AUTOSAR XML (schema 4-2-1)
standard types defined: boolean, float32, sint8, uint16, uint8, boolean_CompuMethod, boolean_DataConstr, float32_DataConstr, sint8_DataConstr, uint16_DataConstr, uint8_DataConstr
package /ComponentTypes
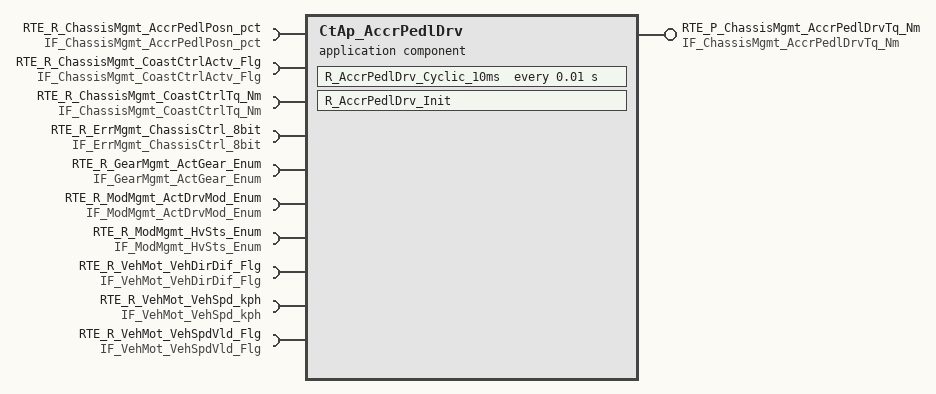
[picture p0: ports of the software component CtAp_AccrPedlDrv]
  application sw component type CtAp_AccrPedlDrv
    provide port RTE_P_ChassisMgmt_AccrPedlDrvTq_Nm: nonqueued-sender-com-spec{data-element=tec_ChassisMgmt_AccrPedlDrvTq_Nm, init-value=0}, provided-interface=IF_ChassisMgmt_AccrPedlDrvTq_Nm
    10 x require port:
      RTE_R_ChassisMgmt_AccrPedlPosn_pct: nonqueued-receiver-com-spec{data-element=tec_ChassisMgmt_AccrPedlPosn_pct, filter=data-filter-type=ALWAYS, init-value=0}, required-interface=IF_ChassisMgmt_AccrPedlPosn_pct
      RTE_R_ChassisMgmt_CoastCtrlActv_Flg: nonqueued-receiver-com-spec{data-element=tec_ChassisMgmt_CoastCtrlActv_Flg, filter=data-filter-type=ALWAYS, init-value=0}, required-interface=IF_ChassisMgmt_CoastCtrlActv_Flg
      RTE_R_ChassisMgmt_CoastCtrlTq_Nm: nonqueued-receiver-com-spec{data-element=tec_ChassisMgmt_CoastCtrlTq_Nm, filter=data-filter-type=ALWAYS, init-value=0}, required-interface=IF_ChassisMgmt_CoastCtrlTq_Nm
      RTE_R_ErrMgmt_ChassisCtrl_8bit: nonqueued-receiver-com-spec{data-element=tec_ErrMgmt_ChassisCtrl_8bit, filter=data-filter-type=ALWAYS, init-value=0}, required-interface=IF_ErrMgmt_ChassisCtrl_8bit
      RTE_R_GearMgmt_ActGear_Enum: nonqueued-receiver-com-spec{data-element=tec_GearMgmt_ActGear_Enum, filter=data-filter-type=ALWAYS, init-value=0}, required-interface=IF_GearMgmt_ActGear_Enum
      RTE_R_ModMgmt_ActDrvMod_Enum: nonqueued-receiver-com-spec{data-element=tec_ModMgmt_ActDrvMod_Enum, filter=data-filter-type=ALWAYS, init-value=0}, required-interface=IF_ModMgmt_ActDrvMod_Enum
      RTE_R_ModMgmt_HvSts_Enum: nonqueued-receiver-com-spec{data-element=tec_ModMgmt_HvSts_Enum, filter=data-filter-type=ALWAYS, init-value=0}, required-interface=IF_ModMgmt_HvSts_Enum
      RTE_R_VehMot_VehDirDif_Flg: nonqueued-receiver-com-spec{data-element=tec_VehMot_VehDirDif_Flg, filter=data-filter-type=ALWAYS, init-value=0}, required-interface=IF_VehMot_VehDirDif_Flg
      RTE_R_VehMot_VehSpd_kph: nonqueued-receiver-com-spec{data-element=tec_VehMot_VehSpd_kph, filter=data-filter-type=ALWAYS, init-value=0}, required-interface=IF_VehMot_VehSpd_kph
      RTE_R_VehMot_VehSpdVld_Flg: nonqueued-receiver-com-spec{data-element=tec_VehMot_VehSpdVld_Flg, filter=data-filter-type=ALWAYS, init-value=0}, required-interface=IF_VehMot_VehSpdVld_Flg
    behavior CtAp_AccrPedlDrv_InternalBehavior
      timing event TMT_R_AccrPedlDrv_Cyclic_10ms: start-on-event=R_AccrPedlDrv_Cyclic_10ms, period=0.01
      init event CtAp_AccrPedlDrv_InitEvent: start-on-event=R_AccrPedlDrv_Init
      runnable R_AccrPedlDrv_Cyclic_10ms
        data-receive-point-by-arguments:
          10 x access:
            REC_RTE_R_ChassisMgmt_AccrPedlPosn_pct_tec_ChassisMgmt_AccrPedlPosn_pct: accessed-variable=RTE_R_ChassisMgmt_AccrPedlPosn_pct.tec_ChassisMgmt_AccrPedlPosn_pct
            REC_RTE_R_ChassisMgmt_CoastCtrlActv_Flg_tec_ChassisMgmt_CoastCtrlActv_Flg: accessed-variable=RTE_R_ChassisMgmt_CoastCtrlActv_Flg.tec_ChassisMgmt_CoastCtrlActv_Flg
            REC_RTE_R_ChassisMgmt_CoastCtrlTq_Nm_tec_ChassisMgmt_CoastCtrlTq_Nm: accessed-variable=RTE_R_ChassisMgmt_CoastCtrlTq_Nm.tec_ChassisMgmt_CoastCtrlTq_Nm
            REC_RTE_R_ErrMgmt_ChassisCtrl_8bit_tec_ErrMgmt_ChassisCtrl_8bit: accessed-variable=RTE_R_ErrMgmt_ChassisCtrl_8bit.tec_ErrMgmt_ChassisCtrl_8bit
            REC_RTE_R_GearMgmt_ActGear_Enum_tec_GearMgmt_ActGear_Enum: accessed-variable=RTE_R_GearMgmt_ActGear_Enum.tec_GearMgmt_ActGear_Enum
            REC_RTE_R_ModMgmt_ActDrvMod_Enum_tec_ModMgmt_ActDrvMod_Enum: accessed-variable=RTE_R_ModMgmt_ActDrvMod_Enum.tec_ModMgmt_ActDrvMod_Enum
            REC_RTE_R_ModMgmt_HvSts_Enum_tec_ModMgmt_HvSts_Enum: accessed-variable=RTE_R_ModMgmt_HvSts_Enum.tec_ModMgmt_HvSts_Enum
            REC_RTE_R_VehMot_VehDirDif_Flg_tec_VehMot_VehDirDif_Flg: accessed-variable=RTE_R_VehMot_VehDirDif_Flg.tec_VehMot_VehDirDif_Flg
            REC_RTE_R_VehMot_VehSpd_kph_tec_VehMot_VehSpd_kph: accessed-variable=RTE_R_VehMot_VehSpd_kph.tec_VehMot_VehSpd_kph
            REC_RTE_R_VehMot_VehSpdVld_Flg_tec_VehMot_VehSpdVld_Flg: accessed-variable=RTE_R_VehMot_VehSpdVld_Flg.tec_VehMot_VehSpdVld_Flg
        data-send-points:
          access SEND_RTE_P_ChassisMgmt_AccrPedlDrvTq_Nm_tec_ChassisMgmt_AccrPedlDrvTq_Nm: accessed-variable=RTE_P_ChassisMgmt_AccrPedlDrvTq_Nm.tec_ChassisMgmt_AccrPedlDrvTq_Nm
      runnable R_AccrPedlDrv_Init
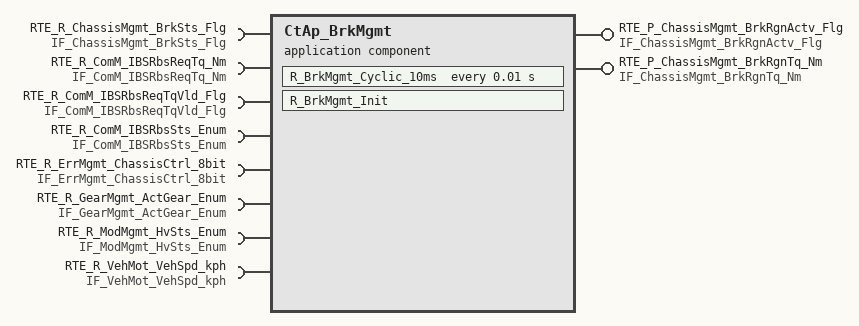
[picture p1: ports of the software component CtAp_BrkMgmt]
  application sw component type CtAp_BrkMgmt
    provide port RTE_P_ChassisMgmt_BrkRgnActv_Flg: nonqueued-sender-com-spec{data-element=tec_ChassisMgmt_BrkRgnActv_Flg, init-value=0}, provided-interface=IF_ChassisMgmt_BrkRgnActv_Flg
    provide port RTE_P_ChassisMgmt_BrkRgnTq_Nm: nonqueued-sender-com-spec{data-element=tec_ChassisMgmt_BrkRgnTq_Nm, init-value=0}, provided-interface=IF_ChassisMgmt_BrkRgnTq_Nm
    8 x require port:
      RTE_R_ChassisMgmt_BrkSts_Flg: nonqueued-receiver-com-spec{data-element=tec_ChassisMgmt_BrkSts_Flg, filter=data-filter-type=ALWAYS, init-value=0}, required-interface=IF_ChassisMgmt_BrkSts_Flg
      RTE_R_ComM_IBSRbsReqTq_Nm: nonqueued-receiver-com-spec{data-element=tec_ComM_IBSRbsReqTq_Nm, filter=data-filter-type=ALWAYS, init-value=0}, required-interface=IF_ComM_IBSRbsReqTq_Nm
      RTE_R_ComM_IBSRbsReqTqVld_Flg: nonqueued-receiver-com-spec{data-element=tec_ComM_IBSRbsReqTqVld_Flg, filter=data-filter-type=ALWAYS, init-value=0}, required-interface=IF_ComM_IBSRbsReqTqVld_Flg
      RTE_R_ComM_IBSRbsSts_Enum: nonqueued-receiver-com-spec{data-element=tec_ComM_IBSRbsSts_Enum, filter=data-filter-type=ALWAYS, init-value=0}, required-interface=IF_ComM_IBSRbsSts_Enum
      RTE_R_ErrMgmt_ChassisCtrl_8bit: nonqueued-receiver-com-spec{data-element=tec_ErrMgmt_ChassisCtrl_8bit, filter=data-filter-type=ALWAYS, init-value=0}, required-interface=IF_ErrMgmt_ChassisCtrl_8bit
      RTE_R_GearMgmt_ActGear_Enum: nonqueued-receiver-com-spec{data-element=tec_GearMgmt_ActGear_Enum, filter=data-filter-type=ALWAYS, init-value=0}, required-interface=IF_GearMgmt_ActGear_Enum
      RTE_R_ModMgmt_HvSts_Enum: nonqueued-receiver-com-spec{data-element=tec_ModMgmt_HvSts_Enum, filter=data-filter-type=ALWAYS, init-value=0}, required-interface=IF_ModMgmt_HvSts_Enum
      RTE_R_VehMot_VehSpd_kph: nonqueued-receiver-com-spec{data-element=tec_VehMot_VehSpd_kph, filter=data-filter-type=ALWAYS, init-value=0}, required-interface=IF_VehMot_VehSpd_kph
    behavior CtAp_BrkMgmt_InternalBehavior
      timing event TMT_R_BrkMgmt_Cyclic_10ms: start-on-event=R_BrkMgmt_Cyclic_10ms, period=0.01
      init event CtAp_BrkMgmt_InitEvent: start-on-event=R_BrkMgmt_Init
      runnable R_BrkMgmt_Cyclic_10ms
        data-receive-point-by-arguments:
          8 x access:
            REC_RTE_R_ChassisMgmt_BrkSts_Flg_tec_ChassisMgmt_BrkSts_Flg: accessed-variable=RTE_R_ChassisMgmt_BrkSts_Flg.tec_ChassisMgmt_BrkSts_Flg
            REC_RTE_R_ComM_IBSRbsReqTq_Nm_tec_ComM_IBSRbsReqTq_Nm: accessed-variable=RTE_R_ComM_IBSRbsReqTq_Nm.tec_ComM_IBSRbsReqTq_Nm
            REC_RTE_R_ComM_IBSRbsReqTqVld_Flg_tec_ComM_IBSRbsReqTqVld_Flg: accessed-variable=RTE_R_ComM_IBSRbsReqTqVld_Flg.tec_ComM_IBSRbsReqTqVld_Flg
            REC_RTE_R_ComM_IBSRbsSts_Enum_tec_ComM_IBSRbsSts_Enum: accessed-variable=RTE_R_ComM_IBSRbsSts_Enum.tec_ComM_IBSRbsSts_Enum
            REC_RTE_R_ErrMgmt_ChassisCtrl_8bit_tec_ErrMgmt_ChassisCtrl_8bit: accessed-variable=RTE_R_ErrMgmt_ChassisCtrl_8bit.tec_ErrMgmt_ChassisCtrl_8bit
            REC_RTE_R_GearMgmt_ActGear_Enum_tec_GearMgmt_ActGear_Enum: accessed-variable=RTE_R_GearMgmt_ActGear_Enum.tec_GearMgmt_ActGear_Enum
            REC_RTE_R_ModMgmt_HvSts_Enum_tec_ModMgmt_HvSts_Enum: accessed-variable=RTE_R_ModMgmt_HvSts_Enum.tec_ModMgmt_HvSts_Enum
            REC_RTE_R_VehMot_VehSpd_kph_tec_VehMot_VehSpd_kph: accessed-variable=RTE_R_VehMot_VehSpd_kph.tec_VehMot_VehSpd_kph
        data-send-points:
          access SEND_RTE_P_ChassisMgmt_BrkRgnActv_Flg_tec_ChassisMgmt_BrkRgnActv_Flg: accessed-variable=RTE_P_ChassisMgmt_BrkRgnActv_Flg.tec_ChassisMgmt_BrkRgnActv_Flg
          access SEND_RTE_P_ChassisMgmt_BrkRgnTq_Nm_tec_ChassisMgmt_BrkRgnTq_Nm: accessed-variable=RTE_P_ChassisMgmt_BrkRgnTq_Nm.tec_ChassisMgmt_BrkRgnTq_Nm
      runnable R_BrkMgmt_Init
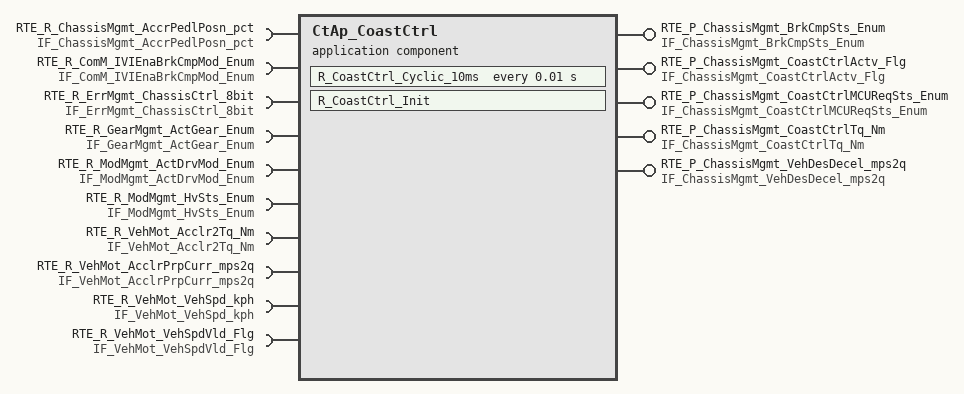
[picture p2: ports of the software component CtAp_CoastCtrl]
  application sw component type CtAp_CoastCtrl
    5 x provide port:
      RTE_P_ChassisMgmt_BrkCmpSts_Enum: nonqueued-sender-com-spec{data-element=tec_ChassisMgmt_BrkCmpSts_Enum, init-value=0}, provided-interface=IF_ChassisMgmt_BrkCmpSts_Enum
      RTE_P_ChassisMgmt_CoastCtrlActv_Flg: nonqueued-sender-com-spec{data-element=tec_ChassisMgmt_CoastCtrlActv_Flg, init-value=0}, provided-interface=IF_ChassisMgmt_CoastCtrlActv_Flg
      RTE_P_ChassisMgmt_CoastCtrlMCUReqSts_Enum: nonqueued-sender-com-spec{data-element=tec_ChassisMgmt_CoastCtrlMCUReqSts_Enum, init-value=0}, provided-interface=IF_ChassisMgmt_CoastCtrlMCUReqSts_Enum
      RTE_P_ChassisMgmt_CoastCtrlTq_Nm: nonqueued-sender-com-spec{data-element=tec_ChassisMgmt_CoastCtrlTq_Nm, init-value=0}, provided-interface=IF_ChassisMgmt_CoastCtrlTq_Nm
      RTE_P_ChassisMgmt_VehDesDecel_mps2q: nonqueued-sender-com-spec{data-element=tec_ChassisMgmt_BrkCmpDesDecel_mps2q, init-value=0}, provided-interface=IF_ChassisMgmt_VehDesDecel_mps2q
    10 x require port:
      RTE_R_ChassisMgmt_AccrPedlPosn_pct: nonqueued-receiver-com-spec{data-element=tec_ChassisMgmt_AccrPedlPosn_pct, filter=data-filter-type=ALWAYS, init-value=0}, required-interface=IF_ChassisMgmt_AccrPedlPosn_pct
      RTE_R_ComM_IVIEnaBrkCmpMod_Enum: nonqueued-receiver-com-spec{data-element=tec_ComM_IVIEnaBrkCmpMod_Enum, filter=data-filter-type=ALWAYS, init-value=0}, required-interface=IF_ComM_IVIEnaBrkCmpMod_Enum
      RTE_R_ErrMgmt_ChassisCtrl_8bit: nonqueued-receiver-com-spec{data-element=tec_ErrMgmt_ChassisCtrl_8bit, filter=data-filter-type=ALWAYS, init-value=0}, required-interface=IF_ErrMgmt_ChassisCtrl_8bit
      RTE_R_GearMgmt_ActGear_Enum: nonqueued-receiver-com-spec{data-element=tec_GearMgmt_ActGear_Enum, filter=data-filter-type=ALWAYS, init-value=0}, required-interface=IF_GearMgmt_ActGear_Enum
      RTE_R_ModMgmt_ActDrvMod_Enum: nonqueued-receiver-com-spec{data-element=tec_ModMgmt_ActDrvMod_Enum, filter=data-filter-type=ALWAYS, init-value=0}, required-interface=IF_ModMgmt_ActDrvMod_Enum
      RTE_R_ModMgmt_HvSts_Enum: nonqueued-receiver-com-spec{data-element=tec_ModMgmt_HvSts_Enum, filter=data-filter-type=ALWAYS, init-value=0}, required-interface=IF_ModMgmt_HvSts_Enum
      RTE_R_VehMot_Acclr2Tq_Nm: nonqueued-receiver-com-spec{data-element=tec_VehMot_Acclr2Tq_Nm, filter=data-filter-type=ALWAYS, init-value=0}, required-interface=IF_VehMot_Acclr2Tq_Nm
      RTE_R_VehMot_AcclrPrpCurr_mps2q: nonqueued-receiver-com-spec{data-element=tec_VehMot_AcclrPrpCurr_mps2q, filter=data-filter-type=ALWAYS, init-value=0}, required-interface=IF_VehMot_AcclrPrpCurr_mps2q
      RTE_R_VehMot_VehSpd_kph: nonqueued-receiver-com-spec{data-element=tec_VehMot_VehSpd_kph, filter=data-filter-type=ALWAYS, init-value=0}, required-interface=IF_VehMot_VehSpd_kph
      RTE_R_VehMot_VehSpdVld_Flg: nonqueued-receiver-com-spec{data-element=tec_VehMot_VehSpdVld_Flg, filter=data-filter-type=ALWAYS, init-value=0}, required-interface=IF_VehMot_VehSpdVld_Flg
    behavior CtAp_CoastCtrl_InternalBehavior
      timing event TMT_R_CoastCtrl_Cyclic_10ms: start-on-event=R_CoastCtrl_Cyclic_10ms, period=0.01
      init event CtAp_CoastCtrl_InitEvent: start-on-event=R_CoastCtrl_Init
      runnable R_CoastCtrl_Cyclic_10ms
        data-receive-point-by-arguments:
          10 x access:
            REC_RTE_R_ChassisMgmt_AccrPedlPosn_pct_tec_ChassisMgmt_AccrPedlPosn_pct: accessed-variable=RTE_R_ChassisMgmt_AccrPedlPosn_pct.tec_ChassisMgmt_AccrPedlPosn_pct
            REC_RTE_R_ComM_IVIEnaBrkCmpMod_Enum_tec_ComM_IVIEnaBrkCmpMod_Enum: accessed-variable=RTE_R_ComM_IVIEnaBrkCmpMod_Enum.tec_ComM_IVIEnaBrkCmpMod_Enum
            REC_RTE_R_ErrMgmt_ChassisCtrl_8bit_tec_ErrMgmt_ChassisCtrl_8bit: accessed-variable=RTE_R_ErrMgmt_ChassisCtrl_8bit.tec_ErrMgmt_ChassisCtrl_8bit
            REC_RTE_R_GearMgmt_ActGear_Enum_tec_GearMgmt_ActGear_Enum: accessed-variable=RTE_R_GearMgmt_ActGear_Enum.tec_GearMgmt_ActGear_Enum
            REC_RTE_R_ModMgmt_ActDrvMod_Enum_tec_ModMgmt_ActDrvMod_Enum: accessed-variable=RTE_R_ModMgmt_ActDrvMod_Enum.tec_ModMgmt_ActDrvMod_Enum
            REC_RTE_R_ModMgmt_HvSts_Enum_tec_ModMgmt_HvSts_Enum: accessed-variable=RTE_R_ModMgmt_HvSts_Enum.tec_ModMgmt_HvSts_Enum
            REC_RTE_R_VehMot_Acclr2Tq_Nm_tec_VehMot_Acclr2Tq_Nm: accessed-variable=RTE_R_VehMot_Acclr2Tq_Nm.tec_VehMot_Acclr2Tq_Nm
            REC_RTE_R_VehMot_AcclrPrpCurr_mps2q_tec_VehMot_AcclrPrpCurr_mps2q: accessed-variable=RTE_R_VehMot_AcclrPrpCurr_mps2q.tec_VehMot_AcclrPrpCurr_mps2q
            REC_RTE_R_VehMot_VehSpd_kph_tec_VehMot_VehSpd_kph: accessed-variable=RTE_R_VehMot_VehSpd_kph.tec_VehMot_VehSpd_kph
            REC_RTE_R_VehMot_VehSpdVld_Flg_tec_VehMot_VehSpdVld_Flg: accessed-variable=RTE_R_VehMot_VehSpdVld_Flg.tec_VehMot_VehSpdVld_Flg
        data-send-points:
          5 x access:
            SEND_RTE_P_ChassisMgmt_BrkCmpSts_Enum_tec_ChassisMgmt_BrkCmpSts_Enum: accessed-variable=RTE_P_ChassisMgmt_BrkCmpSts_Enum.tec_ChassisMgmt_BrkCmpSts_Enum
            SEND_RTE_P_ChassisMgmt_CoastCtrlActv_Flg_tec_ChassisMgmt_CoastCtrlActv_Flg: accessed-variable=RTE_P_ChassisMgmt_CoastCtrlActv_Flg.tec_ChassisMgmt_CoastCtrlActv_Flg
            SEND_RTE_P_ChassisMgmt_CoastCtrlMCUReqSts_Enum_tec_ChassisMgmt_CoastCtrlMCUReqSts_Enum: accessed-variable=RTE_P_ChassisMgmt_CoastCtrlMCUReqSts_Enum.tec_ChassisMgmt_CoastCtrlMCUReqSts_Enum
            SEND_RTE_P_ChassisMgmt_CoastCtrlTq_Nm_tec_ChassisMgmt_CoastCtrlTq_Nm: accessed-variable=RTE_P_ChassisMgmt_CoastCtrlTq_Nm.tec_ChassisMgmt_CoastCtrlTq_Nm
            SEND_RTE_P_ChassisMgmt_VehDesDecel_mps2q_tec_ChassisMgmt_BrkCmpDesDecel_mps2q: accessed-variable=RTE_P_ChassisMgmt_VehDesDecel_mps2q.tec_ChassisMgmt_BrkCmpDesDecel_mps2q
      runnable R_CoastCtrl_Init
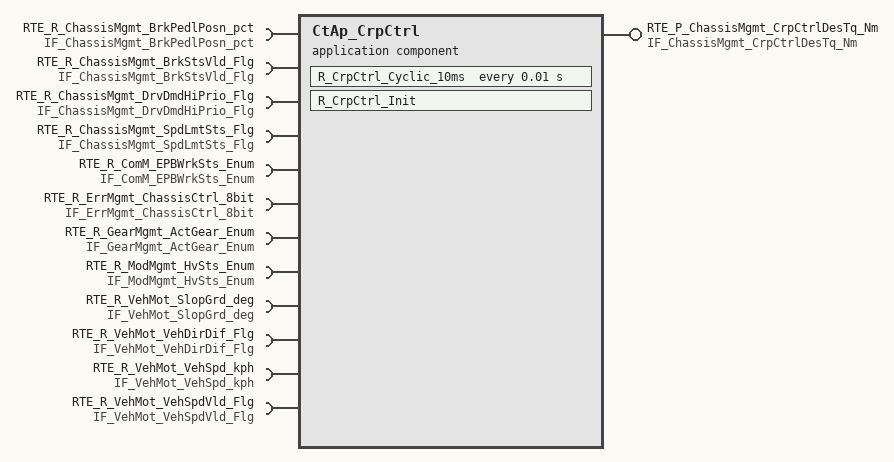
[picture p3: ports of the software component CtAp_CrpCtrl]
  application sw component type CtAp_CrpCtrl
    provide port RTE_P_ChassisMgmt_CrpCtrlDesTq_Nm: nonqueued-sender-com-spec{data-element=tec_ChassisMgmt_CrpCtrlDesTq_Nm, init-value=0}, provided-interface=IF_ChassisMgmt_CrpCtrlDesTq_Nm
    12 x require port:
      RTE_R_ChassisMgmt_BrkPedlPosn_pct: nonqueued-receiver-com-spec{data-element=tec_ChassisMgmt_BrkPedlPosn_pct, filter=data-filter-type=ALWAYS, init-value=0}, required-interface=IF_ChassisMgmt_BrkPedlPosn_pct
      RTE_R_ChassisMgmt_BrkStsVld_Flg: nonqueued-receiver-com-spec{data-element=tec_ChassisMgmt_BrkStsVld_Flg, filter=data-filter-type=ALWAYS, init-value=0}, required-interface=IF_ChassisMgmt_BrkStsVld_Flg
      RTE_R_ChassisMgmt_DrvDmdHiPrio_Flg: nonqueued-receiver-com-spec{data-element=tec_ChassisMgmt_DrvDmdHiPrio_Flg, filter=data-filter-type=ALWAYS, init-value=0}, required-interface=IF_ChassisMgmt_DrvDmdHiPrio_Flg
      RTE_R_ChassisMgmt_SpdLmtSts_Flg: nonqueued-receiver-com-spec{data-element=tec_ChassisMgmt_SpdLmtSts_Flg, filter=data-filter-type=ALWAYS, init-value=0}, required-interface=IF_ChassisMgmt_SpdLmtSts_Flg
      RTE_R_ComM_EPBWrkSts_Enum: nonqueued-receiver-com-spec{data-element=tec_ComM_EPBWrkSts_Enum, filter=data-filter-type=ALWAYS, init-value=0}, required-interface=IF_ComM_EPBWrkSts_Enum
      RTE_R_ErrMgmt_ChassisCtrl_8bit: nonqueued-receiver-com-spec{data-element=tec_ErrMgmt_ChassisCtrl_8bit, filter=data-filter-type=ALWAYS, init-value=0}, required-interface=IF_ErrMgmt_ChassisCtrl_8bit
      RTE_R_GearMgmt_ActGear_Enum: nonqueued-receiver-com-spec{data-element=tec_GearMgmt_ActGear_Enum, filter=data-filter-type=ALWAYS, init-value=0}, required-interface=IF_GearMgmt_ActGear_Enum
      RTE_R_ModMgmt_HvSts_Enum: nonqueued-receiver-com-spec{data-element=tec_ModMgmt_HvSts_Enum, filter=data-filter-type=ALWAYS, init-value=0}, required-interface=IF_ModMgmt_HvSts_Enum
      RTE_R_VehMot_SlopGrd_deg: nonqueued-receiver-com-spec{data-element=tec_VehMot_SlopGrd_deg, filter=data-filter-type=ALWAYS, init-value=0}, required-interface=IF_VehMot_SlopGrd_deg
      RTE_R_VehMot_VehDirDif_Flg: nonqueued-receiver-com-spec{data-element=tec_VehMot_VehDirDif_Flg, filter=data-filter-type=ALWAYS, init-value=0}, required-interface=IF_VehMot_VehDirDif_Flg
      RTE_R_VehMot_VehSpd_kph: nonqueued-receiver-com-spec{data-element=tec_VehMot_VehSpd_kph, filter=data-filter-type=ALWAYS, init-value=0}, required-interface=IF_VehMot_VehSpd_kph
      RTE_R_VehMot_VehSpdVld_Flg: nonqueued-receiver-com-spec{data-element=tec_VehMot_VehSpdVld_Flg, filter=data-filter-type=ALWAYS, init-value=0}, required-interface=IF_VehMot_VehSpdVld_Flg
    behavior CtAp_CrpCtrl_InternalBehavior
      timing event TMT_R_CrpCtrl_Cyclic_10ms: start-on-event=R_CrpCtrl_Cyclic_10ms, period=0.01
      init event CtAp_CrpCtrl_InitEvent: start-on-event=R_CrpCtrl_Init
      runnable R_CrpCtrl_Cyclic_10ms
        data-receive-point-by-arguments:
          12 x access:
            REC_RTE_R_ChassisMgmt_BrkPedlPosn_pct_tec_ChassisMgmt_BrkPedlPosn_pct: accessed-variable=RTE_R_ChassisMgmt_BrkPedlPosn_pct.tec_ChassisMgmt_BrkPedlPosn_pct
            REC_RTE_R_ChassisMgmt_BrkStsVld_Flg_tec_ChassisMgmt_BrkStsVld_Flg: accessed-variable=RTE_R_ChassisMgmt_BrkStsVld_Flg.tec_ChassisMgmt_BrkStsVld_Flg
            REC_RTE_R_ChassisMgmt_DrvDmdHiPrio_Flg_tec_ChassisMgmt_DrvDmdHiPrio_Flg: accessed-variable=RTE_R_ChassisMgmt_DrvDmdHiPrio_Flg.tec_ChassisMgmt_DrvDmdHiPrio_Flg
            REC_RTE_R_ChassisMgmt_SpdLmtSts_Flg_tec_ChassisMgmt_SpdLmtSts_Flg: accessed-variable=RTE_R_ChassisMgmt_SpdLmtSts_Flg.tec_ChassisMgmt_SpdLmtSts_Flg
            REC_RTE_R_ComM_EPBWrkSts_Enum_tec_ComM_EPBWrkSts_Enum: accessed-variable=RTE_R_ComM_EPBWrkSts_Enum.tec_ComM_EPBWrkSts_Enum
            REC_RTE_R_ErrMgmt_ChassisCtrl_8bit_tec_ErrMgmt_ChassisCtrl_8bit: accessed-variable=RTE_R_ErrMgmt_ChassisCtrl_8bit.tec_ErrMgmt_ChassisCtrl_8bit
            REC_RTE_R_GearMgmt_ActGear_Enum_tec_GearMgmt_ActGear_Enum: accessed-variable=RTE_R_GearMgmt_ActGear_Enum.tec_GearMgmt_ActGear_Enum
            REC_RTE_R_ModMgmt_HvSts_Enum_tec_ModMgmt_HvSts_Enum: accessed-variable=RTE_R_ModMgmt_HvSts_Enum.tec_ModMgmt_HvSts_Enum
            REC_RTE_R_VehMot_SlopGrd_deg_tec_VehMot_SlopGrd_deg: accessed-variable=RTE_R_VehMot_SlopGrd_deg.tec_VehMot_SlopGrd_deg
            REC_RTE_R_VehMot_VehDirDif_Flg_tec_VehMot_VehDirDif_Flg: accessed-variable=RTE_R_VehMot_VehDirDif_Flg.tec_VehMot_VehDirDif_Flg
            REC_RTE_R_VehMot_VehSpd_kph_tec_VehMot_VehSpd_kph: accessed-variable=RTE_R_VehMot_VehSpd_kph.tec_VehMot_VehSpd_kph
            REC_RTE_R_VehMot_VehSpdVld_Flg_tec_VehMot_VehSpdVld_Flg: accessed-variable=RTE_R_VehMot_VehSpdVld_Flg.tec_VehMot_VehSpdVld_Flg
        data-send-points:
          access SEND_RTE_P_ChassisMgmt_CrpCtrlDesTq_Nm_tec_ChassisMgmt_CrpCtrlDesTq_Nm: accessed-variable=RTE_P_ChassisMgmt_CrpCtrlDesTq_Nm.tec_ChassisMgmt_CrpCtrlDesTq_Nm
      runnable R_CrpCtrl_Init
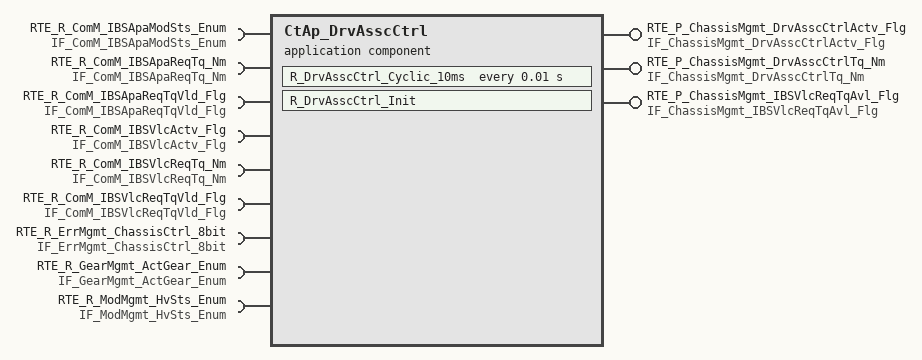
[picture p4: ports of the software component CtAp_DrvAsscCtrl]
  application sw component type CtAp_DrvAsscCtrl
    provide port RTE_P_ChassisMgmt_DrvAsscCtrlActv_Flg: nonqueued-sender-com-spec{data-element=tec_ChassisMgmt_DrvAsscCtrlActv_Flg, init-value=0}, provided-interface=IF_ChassisMgmt_DrvAsscCtrlActv_Flg
    provide port RTE_P_ChassisMgmt_DrvAsscCtrlTq_Nm: nonqueued-sender-com-spec{data-element=tec_ChassisMgmt_DrvAsscCtrlTq_Nm, init-value=0}, provided-interface=IF_ChassisMgmt_DrvAsscCtrlTq_Nm
    provide port RTE_P_ChassisMgmt_IBSVlcReqTqAvl_Flg: nonqueued-sender-com-spec{data-element=tec_ChassisMgmt_IBSVlcReqTqAvl_Flg, init-value=0}, provided-interface=IF_ChassisMgmt_IBSVlcReqTqAvl_Flg
    9 x require port:
      RTE_R_ComM_IBSApaModSts_Enum: nonqueued-receiver-com-spec{data-element=tec_ComM_IBSApaModSts_Enum, filter=data-filter-type=ALWAYS, init-value=0}, required-interface=IF_ComM_IBSApaModSts_Enum
      RTE_R_ComM_IBSApaReqTq_Nm: nonqueued-receiver-com-spec{data-element=tec_ComM_IBSApaReqTq_Nm, filter=data-filter-type=ALWAYS, init-value=0}, required-interface=IF_ComM_IBSApaReqTq_Nm
      RTE_R_ComM_IBSApaReqTqVld_Flg: nonqueued-receiver-com-spec{data-element=tec_ComM_IBSApaReqTqVld_Flg, filter=data-filter-type=ALWAYS, init-value=0}, required-interface=IF_ComM_IBSApaReqTqVld_Flg
      RTE_R_ComM_IBSVlcActv_Flg: nonqueued-receiver-com-spec{data-element=tec_ComM_IBSVlcActv_Flg, filter=data-filter-type=ALWAYS, init-value=0}, required-interface=IF_ComM_IBSVlcActv_Flg
      RTE_R_ComM_IBSVlcReqTq_Nm: nonqueued-receiver-com-spec{data-element=tec_ComM_IBSVlcReqTq_Nm, filter=data-filter-type=ALWAYS, init-value=0}, required-interface=IF_ComM_IBSVlcReqTq_Nm
      RTE_R_ComM_IBSVlcReqTqVld_Flg: nonqueued-receiver-com-spec{data-element=tec_ComM_IBSVlcReqTqVld_Flg, filter=data-filter-type=ALWAYS, init-value=0}, required-interface=IF_ComM_IBSVlcReqTqVld_Flg
      RTE_R_ErrMgmt_ChassisCtrl_8bit: nonqueued-receiver-com-spec{data-element=tec_ErrMgmt_ChassisCtrl_8bit, filter=data-filter-type=ALWAYS, init-value=0}, required-interface=IF_ErrMgmt_ChassisCtrl_8bit
      RTE_R_GearMgmt_ActGear_Enum: nonqueued-receiver-com-spec{data-element=tec_GearMgmt_ActGear_Enum, filter=data-filter-type=ALWAYS, init-value=0}, required-interface=IF_GearMgmt_ActGear_Enum
      RTE_R_ModMgmt_HvSts_Enum: nonqueued-receiver-com-spec{data-element=tec_ModMgmt_HvSts_Enum, filter=data-filter-type=ALWAYS, init-value=0}, required-interface=IF_ModMgmt_HvSts_Enum
    behavior CtAp_DrvAsscCtrl_InternalBehavior
      timing event TMT_R_DrvAsscCtrl_Cyclic_10ms: start-on-event=R_DrvAsscCtrl_Cyclic_10ms, period=0.01
      init event CtAp_DrvAsscCtrl_InitEvent: start-on-event=R_DrvAsscCtrl_Init
      runnable R_DrvAsscCtrl_Cyclic_10ms
        data-receive-point-by-arguments:
          9 x access:
            REC_RTE_R_ComM_IBSApaModSts_Enum_tec_ComM_IBSApaModSts_Enum: accessed-variable=RTE_R_ComM_IBSApaModSts_Enum.tec_ComM_IBSApaModSts_Enum
            REC_RTE_R_ComM_IBSApaReqTq_Nm_tec_ComM_IBSApaReqTq_Nm: accessed-variable=RTE_R_ComM_IBSApaReqTq_Nm.tec_ComM_IBSApaReqTq_Nm
            REC_RTE_R_ComM_IBSApaReqTqVld_Flg_tec_ComM_IBSApaReqTqVld_Flg: accessed-variable=RTE_R_ComM_IBSApaReqTqVld_Flg.tec_ComM_IBSApaReqTqVld_Flg
            REC_RTE_R_ComM_IBSVlcActv_Flg_tec_ComM_IBSVlcActv_Flg: accessed-variable=RTE_R_ComM_IBSVlcActv_Flg.tec_ComM_IBSVlcActv_Flg
            REC_RTE_R_ComM_IBSVlcReqTq_Nm_tec_ComM_IBSVlcReqTq_Nm: accessed-variable=RTE_R_ComM_IBSVlcReqTq_Nm.tec_ComM_IBSVlcReqTq_Nm
            REC_RTE_R_ComM_IBSVlcReqTqVld_Flg_tec_ComM_IBSVlcReqTqVld_Flg: accessed-variable=RTE_R_ComM_IBSVlcReqTqVld_Flg.tec_ComM_IBSVlcReqTqVld_Flg
            REC_RTE_R_ErrMgmt_ChassisCtrl_8bit_tec_ErrMgmt_ChassisCtrl_8bit: accessed-variable=RTE_R_ErrMgmt_ChassisCtrl_8bit.tec_ErrMgmt_ChassisCtrl_8bit
            REC_RTE_R_GearMgmt_ActGear_Enum_tec_GearMgmt_ActGear_Enum: accessed-variable=RTE_R_GearMgmt_ActGear_Enum.tec_GearMgmt_ActGear_Enum
            REC_RTE_R_ModMgmt_HvSts_Enum_tec_ModMgmt_HvSts_Enum: accessed-variable=RTE_R_ModMgmt_HvSts_Enum.tec_ModMgmt_HvSts_Enum
        data-send-points:
          access SEND_RTE_P_ChassisMgmt_DrvAsscCtrlActv_Flg_tec_ChassisMgmt_DrvAsscCtrlActv_Flg: accessed-variable=RTE_P_ChassisMgmt_DrvAsscCtrlActv_Flg.tec_ChassisMgmt_DrvAsscCtrlActv_Flg
          access SEND_RTE_P_ChassisMgmt_DrvAsscCtrlTq_Nm_tec_ChassisMgmt_DrvAsscCtrlTq_Nm: accessed-variable=RTE_P_ChassisMgmt_DrvAsscCtrlTq_Nm.tec_ChassisMgmt_DrvAsscCtrlTq_Nm
          access SEND_RTE_P_ChassisMgmt_IBSVlcReqTqAvl_Flg_tec_ChassisMgmt_IBSVlcReqTqAvl_Flg: accessed-variable=RTE_P_ChassisMgmt_IBSVlcReqTqAvl_Flg.tec_ChassisMgmt_IBSVlcReqTqAvl_Flg
      runnable R_DrvAsscCtrl_Init
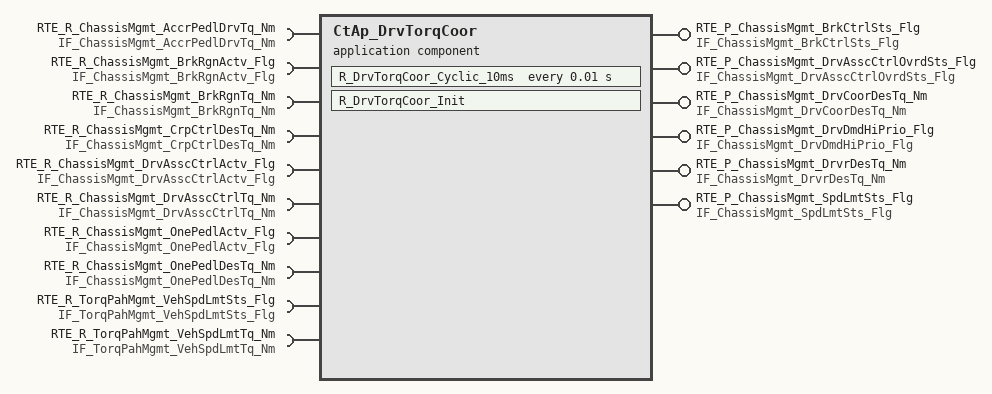
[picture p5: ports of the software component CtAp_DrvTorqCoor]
  application sw component type CtAp_DrvTorqCoor
    6 x provide port:
      RTE_P_ChassisMgmt_BrkCtrlSts_Flg: nonqueued-sender-com-spec{data-element=tec_ChassisMgmt_BrkCtrlSts_Flg, init-value=0}, provided-interface=IF_ChassisMgmt_BrkCtrlSts_Flg
      RTE_P_ChassisMgmt_DrvAsscCtrlOvrdSts_Flg: nonqueued-sender-com-spec{data-element=tec_ChassisMgmt_DrvAsscCtrlOvrdSts_Flg, init-value=0}, provided-interface=IF_ChassisMgmt_DrvAsscCtrlOvrdSts_Flg
      RTE_P_ChassisMgmt_DrvCoorDesTq_Nm: nonqueued-sender-com-spec{data-element=tec_ChassisMgmt_DrvCoorDesTq_Nm, init-value=0}, provided-interface=IF_ChassisMgmt_DrvCoorDesTq_Nm
      RTE_P_ChassisMgmt_DrvDmdHiPrio_Flg: nonqueued-sender-com-spec{data-element=tec_ChassisMgmt_DrvDmdHiPrio_Flg, init-value=0}, provided-interface=IF_ChassisMgmt_DrvDmdHiPrio_Flg
      RTE_P_ChassisMgmt_DrvrDesTq_Nm: nonqueued-sender-com-spec{data-element=tec_ChassisMgmt_DrvrDesTq_Nm, init-value=0}, provided-interface=IF_ChassisMgmt_DrvrDesTq_Nm
      RTE_P_ChassisMgmt_SpdLmtSts_Flg: nonqueued-sender-com-spec{data-element=tec_ChassisMgmt_SpdLmtSts_Flg, init-value=0}, provided-interface=IF_ChassisMgmt_SpdLmtSts_Flg
    10 x require port:
      RTE_R_ChassisMgmt_AccrPedlDrvTq_Nm: nonqueued-receiver-com-spec{data-element=tec_ChassisMgmt_AccrPedlDrvTq_Nm, filter=data-filter-type=ALWAYS, init-value=0}, required-interface=IF_ChassisMgmt_AccrPedlDrvTq_Nm
      RTE_R_ChassisMgmt_BrkRgnActv_Flg: nonqueued-receiver-com-spec{data-element=tec_ChassisMgmt_BrkRgnActv_Flg, filter=data-filter-type=ALWAYS, init-value=0}, required-interface=IF_ChassisMgmt_BrkRgnActv_Flg
      RTE_R_ChassisMgmt_BrkRgnTq_Nm: nonqueued-receiver-com-spec{data-element=tec_ChassisMgmt_BrkRgnTq_Nm, filter=data-filter-type=ALWAYS, init-value=0}, required-interface=IF_ChassisMgmt_BrkRgnTq_Nm
      RTE_R_ChassisMgmt_CrpCtrlDesTq_Nm: nonqueued-receiver-com-spec{data-element=tec_ChassisMgmt_CrpCtrlDesTq_Nm, filter=data-filter-type=ALWAYS, init-value=0}, required-interface=IF_ChassisMgmt_CrpCtrlDesTq_Nm
      RTE_R_ChassisMgmt_DrvAsscCtrlActv_Flg: nonqueued-receiver-com-spec{data-element=tec_ChassisMgmt_DrvAsscCtrlActv_Flg, filter=data-filter-type=ALWAYS, init-value=0}, required-interface=IF_ChassisMgmt_DrvAsscCtrlActv_Flg
      RTE_R_ChassisMgmt_DrvAsscCtrlTq_Nm: nonqueued-receiver-com-spec{data-element=tec_ChassisMgmt_DrvAsscCtrlTq_Nm, filter=data-filter-type=ALWAYS, init-value=0}, required-interface=IF_ChassisMgmt_DrvAsscCtrlTq_Nm
      RTE_R_ChassisMgmt_OnePedlActv_Flg: nonqueued-receiver-com-spec{data-element=tec_ChassisMgmt_OnePedlActv_Flg, filter=data-filter-type=ALWAYS, init-value=0}, required-interface=IF_ChassisMgmt_OnePedlActv_Flg
      RTE_R_ChassisMgmt_OnePedlDesTq_Nm: nonqueued-receiver-com-spec{data-element=tec_ChassisMgmt_OnePedlDesTq_Nm, filter=data-filter-type=ALWAYS, init-value=0}, required-interface=IF_ChassisMgmt_OnePedlDesTq_Nm
      RTE_R_TorqPahMgmt_VehSpdLmtSts_Flg: nonqueued-receiver-com-spec{data-element=tec_TorqPahMgmt_VehSpdLmtSts_Flg, filter=data-filter-type=ALWAYS, init-value=0}, required-interface=IF_TorqPahMgmt_VehSpdLmtSts_Flg
      RTE_R_TorqPahMgmt_VehSpdLmtTq_Nm: nonqueued-receiver-com-spec{data-element=tec_TorqPahMgmt_VehSpdLmtTq_Nm, filter=data-filter-type=ALWAYS, init-value=0}, required-interface=IF_TorqPahMgmt_VehSpdLmtTq_Nm
    behavior CtAp_DrvTorqCoor_InternalBehavior
      timing event TMT_R_DrvTorqCoor_Cyclic_10ms: start-on-event=R_DrvTorqCoor_Cyclic_10ms, period=0.01
      init event CtAp_DrvTorqCoor_InitEvent: start-on-event=R_DrvTorqCoor_Init
      runnable R_DrvTorqCoor_Cyclic_10ms
        data-receive-point-by-arguments:
          10 x access:
            REC_RTE_R_ChassisMgmt_AccrPedlDrvTq_Nm_tec_ChassisMgmt_AccrPedlDrvTq_Nm: accessed-variable=RTE_R_ChassisMgmt_AccrPedlDrvTq_Nm.tec_ChassisMgmt_AccrPedlDrvTq_Nm
            REC_RTE_R_ChassisMgmt_BrkRgnActv_Flg_tec_ChassisMgmt_BrkRgnActv_Flg: accessed-variable=RTE_R_ChassisMgmt_BrkRgnActv_Flg.tec_ChassisMgmt_BrkRgnActv_Flg
            REC_RTE_R_ChassisMgmt_BrkRgnTq_Nm_tec_ChassisMgmt_BrkRgnTq_Nm: accessed-variable=RTE_R_ChassisMgmt_BrkRgnTq_Nm.tec_ChassisMgmt_BrkRgnTq_Nm
            REC_RTE_R_ChassisMgmt_CrpCtrlDesTq_Nm_tec_ChassisMgmt_CrpCtrlDesTq_Nm: accessed-variable=RTE_R_ChassisMgmt_CrpCtrlDesTq_Nm.tec_ChassisMgmt_CrpCtrlDesTq_Nm
            REC_RTE_R_ChassisMgmt_DrvAsscCtrlActv_Flg_tec_ChassisMgmt_DrvAsscCtrlActv_Flg: accessed-variable=RTE_R_ChassisMgmt_DrvAsscCtrlActv_Flg.tec_ChassisMgmt_DrvAsscCtrlActv_Flg
            REC_RTE_R_ChassisMgmt_DrvAsscCtrlTq_Nm_tec_ChassisMgmt_DrvAsscCtrlTq_Nm: accessed-variable=RTE_R_ChassisMgmt_DrvAsscCtrlTq_Nm.tec_ChassisMgmt_DrvAsscCtrlTq_Nm
            REC_RTE_R_ChassisMgmt_OnePedlActv_Flg_tec_ChassisMgmt_OnePedlActv_Flg: accessed-variable=RTE_R_ChassisMgmt_OnePedlActv_Flg.tec_ChassisMgmt_OnePedlActv_Flg
            REC_RTE_R_ChassisMgmt_OnePedlDesTq_Nm_tec_ChassisMgmt_OnePedlDesTq_Nm: accessed-variable=RTE_R_ChassisMgmt_OnePedlDesTq_Nm.tec_ChassisMgmt_OnePedlDesTq_Nm
            REC_RTE_R_TorqPahMgmt_VehSpdLmtSts_Flg_tec_TorqPahMgmt_VehSpdLmtSts_Flg: accessed-variable=RTE_R_TorqPahMgmt_VehSpdLmtSts_Flg.tec_TorqPahMgmt_VehSpdLmtSts_Flg
            REC_RTE_R_TorqPahMgmt_VehSpdLmtTq_Nm_tec_TorqPahMgmt_VehSpdLmtTq_Nm: accessed-variable=RTE_R_TorqPahMgmt_VehSpdLmtTq_Nm.tec_TorqPahMgmt_VehSpdLmtTq_Nm
        data-send-points:
          6 x access:
            SEND_RTE_P_ChassisMgmt_BrkCtrlSts_Flg_tec_ChassisMgmt_BrkCtrlSts_Flg: accessed-variable=RTE_P_ChassisMgmt_BrkCtrlSts_Flg.tec_ChassisMgmt_BrkCtrlSts_Flg
            SEND_RTE_P_ChassisMgmt_DrvAsscCtrlOvrdSts_Flg_tec_ChassisMgmt_DrvAsscCtrlOvrdSts_Flg: accessed-variable=RTE_P_ChassisMgmt_DrvAsscCtrlOvrdSts_Flg.tec_ChassisMgmt_DrvAsscCtrlOvrdSts_Flg
            SEND_RTE_P_ChassisMgmt_DrvCoorDesTq_Nm_tec_ChassisMgmt_DrvCoorDesTq_Nm: accessed-variable=RTE_P_ChassisMgmt_DrvCoorDesTq_Nm.tec_ChassisMgmt_DrvCoorDesTq_Nm
            SEND_RTE_P_ChassisMgmt_DrvDmdHiPrio_Flg_tec_ChassisMgmt_DrvDmdHiPrio_Flg: accessed-variable=RTE_P_ChassisMgmt_DrvDmdHiPrio_Flg.tec_ChassisMgmt_DrvDmdHiPrio_Flg
            SEND_RTE_P_ChassisMgmt_DrvrDesTq_Nm_tec_ChassisMgmt_DrvrDesTq_Nm: accessed-variable=RTE_P_ChassisMgmt_DrvrDesTq_Nm.tec_ChassisMgmt_DrvrDesTq_Nm
            SEND_RTE_P_ChassisMgmt_SpdLmtSts_Flg_tec_ChassisMgmt_SpdLmtSts_Flg: accessed-variable=RTE_P_ChassisMgmt_SpdLmtSts_Flg.tec_ChassisMgmt_SpdLmtSts_Flg
      runnable R_DrvTorqCoor_Init
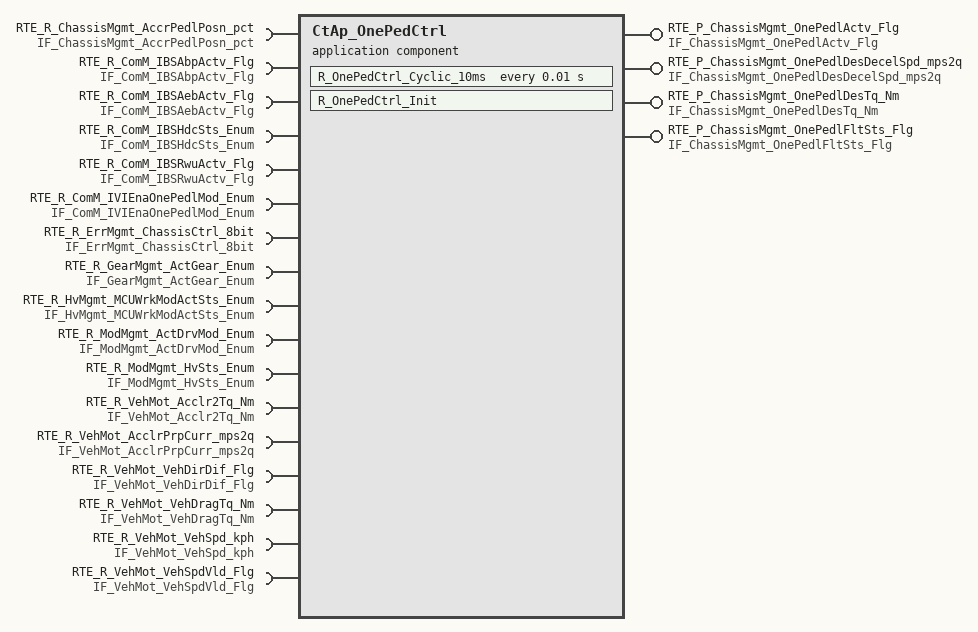
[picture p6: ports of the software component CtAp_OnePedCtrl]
  application sw component type CtAp_OnePedCtrl
    4 x provide port:
      RTE_P_ChassisMgmt_OnePedlActv_Flg: nonqueued-sender-com-spec{data-element=tec_ChassisMgmt_OnePedlActv_Flg, init-value=0}, provided-interface=IF_ChassisMgmt_OnePedlActv_Flg
      RTE_P_ChassisMgmt_OnePedlDesDecelSpd_mps2q: nonqueued-sender-com-spec{data-element=tec_ChassisMgmt_OnePedlDesDecelSpd_mps2q, init-value=0}, provided-interface=IF_ChassisMgmt_OnePedlDesDecelSpd_mps2q
      RTE_P_ChassisMgmt_OnePedlDesTq_Nm: nonqueued-sender-com-spec{data-element=tec_ChassisMgmt_OnePedlDesTq_Nm, init-value=0}, provided-interface=IF_ChassisMgmt_OnePedlDesTq_Nm
      RTE_P_ChassisMgmt_OnePedlFltSts_Flg: nonqueued-sender-com-spec{data-element=tec_ChassisMgmt_OnePedlFltSts_Flg, init-value=0}, provided-interface=IF_ChassisMgmt_OnePedlFltSts_Flg
    17 x require port:
      RTE_R_ChassisMgmt_AccrPedlPosn_pct: nonqueued-receiver-com-spec{data-element=tec_ChassisMgmt_AccrPedlPosn_pct, filter=data-filter-type=ALWAYS, init-value=0}, required-interface=IF_ChassisMgmt_AccrPedlPosn_pct
      RTE_R_ComM_IBSAbpActv_Flg: nonqueued-receiver-com-spec{data-element=tec_ComM_IBSAbpActv_Flg, filter=data-filter-type=ALWAYS, init-value=0}, required-interface=IF_ComM_IBSAbpActv_Flg
      RTE_R_ComM_IBSAebActv_Flg: nonqueued-receiver-com-spec{data-element=tec_ComM_IBSAebActv_Flg, filter=data-filter-type=ALWAYS, init-value=0}, required-interface=IF_ComM_IBSAebActv_Flg
      RTE_R_ComM_IBSHdcSts_Enum: nonqueued-receiver-com-spec{data-element=tec_ComM_IBSHdcSts_Enum, filter=data-filter-type=ALWAYS, init-value=0}, required-interface=IF_ComM_IBSHdcSts_Enum
      RTE_R_ComM_IBSRwuActv_Flg: nonqueued-receiver-com-spec{data-element=tec_ComM_IBSRwuActv_Flg, filter=data-filter-type=ALWAYS, init-value=0}, required-interface=IF_ComM_IBSRwuActv_Flg
      RTE_R_ComM_IVIEnaOnePedlMod_Enum: nonqueued-receiver-com-spec{data-element=tec_ComM_IVIEnaOnePedlMod_Enum, filter=data-filter-type=ALWAYS, init-value=0}, required-interface=IF_ComM_IVIEnaOnePedlMod_Enum
      RTE_R_ErrMgmt_ChassisCtrl_8bit: nonqueued-receiver-com-spec{data-element=tec_ErrMgmt_ChassisCtrl_8bit, filter=data-filter-type=ALWAYS, init-value=0}, required-interface=IF_ErrMgmt_ChassisCtrl_8bit
      RTE_R_GearMgmt_ActGear_Enum: nonqueued-receiver-com-spec{data-element=tec_GearMgmt_ActGear_Enum, filter=data-filter-type=ALWAYS, init-value=0}, required-interface=IF_GearMgmt_ActGear_Enum
      RTE_R_HvMgmt_MCUWrkModActSts_Enum: nonqueued-receiver-com-spec{data-element=tec_HvMgmt_MCUWrkModActSts_Enum, filter=data-filter-type=ALWAYS, init-value=0}, required-interface=IF_HvMgmt_MCUWrkModActSts_Enum
      RTE_R_ModMgmt_ActDrvMod_Enum: nonqueued-receiver-com-spec{data-element=tec_ModMgmt_ActDrvMod_Enum, filter=data-filter-type=ALWAYS, init-value=0}, required-interface=IF_ModMgmt_ActDrvMod_Enum
      RTE_R_ModMgmt_HvSts_Enum: nonqueued-receiver-com-spec{data-element=tec_ModMgmt_HvSts_Enum, filter=data-filter-type=ALWAYS, init-value=0}, required-interface=IF_ModMgmt_HvSts_Enum
      RTE_R_VehMot_Acclr2Tq_Nm: nonqueued-receiver-com-spec{data-element=tec_VehMot_Acclr2Tq_Nm, filter=data-filter-type=ALWAYS, init-value=0}, required-interface=IF_VehMot_Acclr2Tq_Nm
      RTE_R_VehMot_AcclrPrpCurr_mps2q: nonqueued-receiver-com-spec{data-element=tec_VehMot_AcclrPrpCurr_mps2q, filter=data-filter-type=ALWAYS, init-value=0}, required-interface=IF_VehMot_AcclrPrpCurr_mps2q
      RTE_R_VehMot_VehDirDif_Flg: nonqueued-receiver-com-spec{data-element=tec_VehMot_VehDirDif_Flg, filter=data-filter-type=ALWAYS, init-value=0}, required-interface=IF_VehMot_VehDirDif_Flg
      RTE_R_VehMot_VehDragTq_Nm: nonqueued-receiver-com-spec{data-element=tec_VehMot_VehDragTq_Nm, filter=data-filter-type=ALWAYS, init-value=0}, required-interface=IF_VehMot_VehDragTq_Nm
      RTE_R_VehMot_VehSpd_kph: nonqueued-receiver-com-spec{data-element=tec_VehMot_VehSpd_kph, filter=data-filter-type=ALWAYS, init-value=0}, required-interface=IF_VehMot_VehSpd_kph
      RTE_R_VehMot_VehSpdVld_Flg: nonqueued-receiver-com-spec{data-element=tec_VehMot_VehSpdVld_Flg, filter=data-filter-type=ALWAYS, init-value=0}, required-interface=IF_VehMot_VehSpdVld_Flg
    behavior CtAp_OnePedCtrl_InternalBehavior
      timing event TMT_R_OnePedCtrl_Cyclic_10ms: start-on-event=R_OnePedCtrl_Cyclic_10ms, period=0.01
      init event CtAp_OnePedCtrl_InitEvent: start-on-event=R_OnePedCtrl_Init
      runnable R_OnePedCtrl_Cyclic_10ms
        data-receive-point-by-arguments:
          17 x access:
            REC_RTE_R_ChassisMgmt_AccrPedlPosn_pct_tec_ChassisMgmt_AccrPedlPosn_pct: accessed-variable=RTE_R_ChassisMgmt_AccrPedlPosn_pct.tec_ChassisMgmt_AccrPedlPosn_pct
            REC_RTE_R_ComM_IBSAbpActv_Flg_tec_ComM_IBSAbpActv_Flg: accessed-variable=RTE_R_ComM_IBSAbpActv_Flg.tec_ComM_IBSAbpActv_Flg
            REC_RTE_R_ComM_IBSAebActv_Flg_tec_ComM_IBSAebActv_Flg: accessed-variable=RTE_R_ComM_IBSAebActv_Flg.tec_ComM_IBSAebActv_Flg
            REC_RTE_R_ComM_IBSHdcSts_Enum_tec_ComM_IBSHdcSts_Enum: accessed-variable=RTE_R_ComM_IBSHdcSts_Enum.tec_ComM_IBSHdcSts_Enum
            REC_RTE_R_ComM_IBSRwuActv_Flg_tec_ComM_IBSRwuActv_Flg: accessed-variable=RTE_R_ComM_IBSRwuActv_Flg.tec_ComM_IBSRwuActv_Flg
            REC_RTE_R_Comm_IVIEnaOnePedlMod_Enum_tec_ComM_IVIEnaOnePedlMod_Enum: accessed-variable=RTE_R_ComM_IVIEnaOnePedlMod_Enum.tec_ComM_IVIEnaOnePedlMod_Enum
            REC_RTE_R_ErrMgmt_ChassisCtrl_8bit_tec_ErrMgmt_ChassisCtrl_8bit: accessed-variable=RTE_R_ErrMgmt_ChassisCtrl_8bit.tec_ErrMgmt_ChassisCtrl_8bit
            REC_RTE_R_GearMgmt_ActGear_Enum_tec_GearMgmt_ActGear_Enum: accessed-variable=RTE_R_GearMgmt_ActGear_Enum.tec_GearMgmt_ActGear_Enum
            REC_RTE_R_HvMgmt_MCUWrkModActSts_Enum_tec_HvMgmt_MCUWrkModActSts_Enum: accessed-variable=RTE_R_HvMgmt_MCUWrkModActSts_Enum.tec_HvMgmt_MCUWrkModActSts_Enum
            REC_RTE_R_ModMgmt_ActDrvMod_Enum_tec_ModMgmt_ActDrvMod_Enum: accessed-variable=RTE_R_ModMgmt_ActDrvMod_Enum.tec_ModMgmt_ActDrvMod_Enum
            REC_RTE_R_ModMgmt_HvSts_Enum_tec_ModMgmt_HvSts_Enum: accessed-variable=RTE_R_ModMgmt_HvSts_Enum.tec_ModMgmt_HvSts_Enum
            REC_RTE_R_VehMot_Acclr2Tq_Nm_tec_VehMot_Acclr2Tq_Nm: accessed-variable=RTE_R_VehMot_Acclr2Tq_Nm.tec_VehMot_Acclr2Tq_Nm
            REC_RTE_R_VehMot_AcclrPrpCurr_mps2q_tec_VehMot_AcclrPrpCurr_mps2q: accessed-variable=RTE_R_VehMot_AcclrPrpCurr_mps2q.tec_VehMot_AcclrPrpCurr_mps2q
            REC_RTE_R_VehMot_VehDirDif_Flg_tec_VehMot_VehDirDif_Flg: accessed-variable=RTE_R_VehMot_VehDirDif_Flg.tec_VehMot_VehDirDif_Flg
            REC_RTE_R_VehMot_VehDragTq_Nm_tec_VehMot_VehDragTq_Nm: accessed-variable=RTE_R_VehMot_VehDragTq_Nm.tec_VehMot_VehDragTq_Nm
            REC_RTE_R_VehMot_VehSpd_kph_tec_VehMot_VehSpd_kph: accessed-variable=RTE_R_VehMot_VehSpd_kph.tec_VehMot_VehSpd_kph
            REC_RTE_R_VehMot_VehSpdVld_Flg_tec_VehMot_VehSpdVld_Flg: accessed-variable=RTE_R_VehMot_VehSpdVld_Flg.tec_VehMot_VehSpdVld_Flg
        data-send-points:
          4 x access:
            SEND_RTE_P_ChassisMgmt_OnePedlActv_Flg_tec_ChassisMgmt_OnePedlActv_Flg: accessed-variable=RTE_P_ChassisMgmt_OnePedlActv_Flg.tec_ChassisMgmt_OnePedlActv_Flg
            SEND_RTE_P_ChassisMgmt_OnePedlDesDecelSpd_mps2q_tec_ChassisMgmt_OnePedlDesDecelSpd_mps2q: accessed-variable=RTE_P_ChassisMgmt_OnePedlDesDecelSpd_mps2q.tec_ChassisMgmt_OnePedlDesDecelSpd_mps2q
            SEND_RTE_P_ChassisMgmt_OnePedlDesTq_Nm_tec_ChassisMgmt_OnePedlDesTq_Nm: accessed-variable=RTE_P_ChassisMgmt_OnePedlDesTq_Nm.tec_ChassisMgmt_OnePedlDesTq_Nm
            SEND_RTE_P_ChassisMgmt_OnePedlFltSts_Flg_tec_ChassisMgmt_OnePedlFltSts_Flg: accessed-variable=RTE_P_ChassisMgmt_OnePedlFltSts_Flg.tec_ChassisMgmt_OnePedlFltSts_Flg
      runnable R_OnePedCtrl_Init
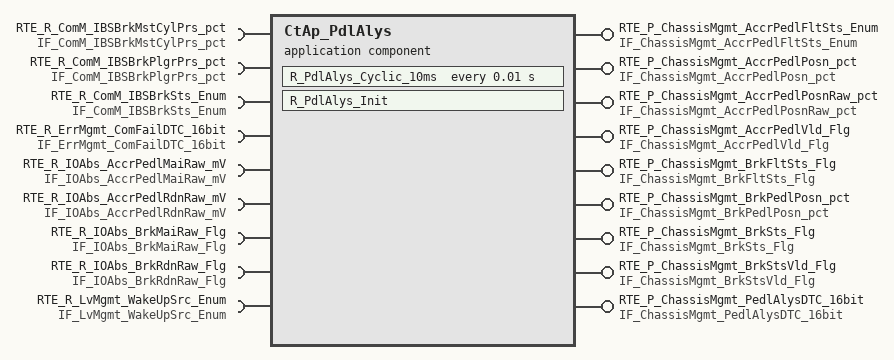
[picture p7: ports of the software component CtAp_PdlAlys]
  application sw component type CtAp_PdlAlys
    9 x provide port:
      RTE_P_ChassisMgmt_AccrPedlFltSts_Enum: nonqueued-sender-com-spec{data-element=tec_ChassisMgmt_AccrPedlFltSts_Enum, init-value=0}, provided-interface=IF_ChassisMgmt_AccrPedlFltSts_Enum
      RTE_P_ChassisMgmt_AccrPedlPosn_pct: nonqueued-sender-com-spec{data-element=tec_ChassisMgmt_AccrPedlPosn_pct, init-value=0}, provided-interface=IF_ChassisMgmt_AccrPedlPosn_pct
      RTE_P_ChassisMgmt_AccrPedlPosnRaw_pct: nonqueued-sender-com-spec{data-element=tec_ChassisMgmt_AccrPedlPosnRaw_pct, init-value=0}, provided-interface=IF_ChassisMgmt_AccrPedlPosnRaw_pct
      RTE_P_ChassisMgmt_AccrPedlVld_Flg: nonqueued-sender-com-spec{data-element=tec_ChassisMgmt_AccrPedlVld_Flg, init-value=0}, provided-interface=IF_ChassisMgmt_AccrPedlVld_Flg
      RTE_P_ChassisMgmt_BrkFltSts_Flg: nonqueued-sender-com-spec{data-element=tec_ChassisMgmt_BrkFltSts_Flg, init-value=0}, provided-interface=IF_ChassisMgmt_BrkFltSts_Flg
      RTE_P_ChassisMgmt_BrkPedlPosn_pct: nonqueued-sender-com-spec{data-element=tec_ChassisMgmt_BrkPedlPosn_pct, init-value=0}, provided-interface=IF_ChassisMgmt_BrkPedlPosn_pct
      RTE_P_ChassisMgmt_BrkSts_Flg: nonqueued-sender-com-spec{data-element=tec_ChassisMgmt_BrkSts_Flg, init-value=0}, provided-interface=IF_ChassisMgmt_BrkSts_Flg
      RTE_P_ChassisMgmt_BrkStsVld_Flg: nonqueued-sender-com-spec{data-element=tec_ChassisMgmt_BrkStsVld_Flg, init-value=0}, provided-interface=IF_ChassisMgmt_BrkStsVld_Flg
      RTE_P_ChassisMgmt_PedlAlysDTC_16bit: nonqueued-sender-com-spec{data-element=tec_ChassisMgmt_PedlAlysDTC_16bit, init-value=0}, provided-interface=IF_ChassisMgmt_PedlAlysDTC_16bit
    9 x require port:
      RTE_R_ComM_IBSBrkMstCylPrs_pct: nonqueued-receiver-com-spec{data-element=tec_ComM_IBSBrkMstCylPrs_pct, filter=data-filter-type=ALWAYS, init-value=0}, required-interface=IF_ComM_IBSBrkMstCylPrs_pct
      RTE_R_ComM_IBSBrkPlgrPrs_pct: nonqueued-receiver-com-spec{data-element=tec_ComM_IBSBrkPlgrPrs_pct, filter=data-filter-type=ALWAYS, init-value=0}, required-interface=IF_ComM_IBSBrkPlgrPrs_pct
      RTE_R_ComM_IBSBrkSts_Enum: nonqueued-receiver-com-spec{data-element=tec_ComM_IBSBrkSts_Enum, filter=data-filter-type=ALWAYS, init-value=0}, required-interface=IF_ComM_IBSBrkSts_Enum
      RTE_R_ErrMgmt_ComFailDTC_16bit: nonqueued-receiver-com-spec{data-element=tec_ErrMgmt_ComFailDTC_16bit, filter=data-filter-type=ALWAYS, init-value=0}, required-interface=IF_ErrMgmt_ComFailDTC_16bit
      RTE_R_IOAbs_AccrPedlMaiRaw_mV: nonqueued-receiver-com-spec{data-element=tec_IOAbs_AccrPedlMaiRaw_mV, filter=data-filter-type=ALWAYS, init-value=0}, required-interface=IF_IOAbs_AccrPedlMaiRaw_mV
      RTE_R_IOAbs_AccrPedlRdnRaw_mV: nonqueued-receiver-com-spec{data-element=tec_IOAbs_AccrPedlRdnRaw_mV, filter=data-filter-type=ALWAYS, init-value=0}, required-interface=IF_IOAbs_AccrPedlRdnRaw_mV
      RTE_R_IOAbs_BrkMaiRaw_Flg: nonqueued-receiver-com-spec{data-element=tec_IOAbs_BrkMaiRaw_Flg, filter=data-filter-type=ALWAYS, init-value=0}, required-interface=IF_IOAbs_BrkMaiRaw_Flg
      RTE_R_IOAbs_BrkRdnRaw_Flg: nonqueued-receiver-com-spec{data-element=tec_IOAbs_BrkRdnRaw_Flg, filter=data-filter-type=ALWAYS, init-value=0}, required-interface=IF_IOAbs_BrkRdnRaw_Flg
      RTE_R_LvMgmt_WakeUpSrc_Enum: nonqueued-receiver-com-spec{data-element=tec_LvMgmt_WakeUpSrc_Enum, filter=data-filter-type=ALWAYS, init-value=0}, required-interface=IF_LvMgmt_WakeUpSrc_Enum
    behavior CtAp_PdlAlys_InternalBehavior
      timing event TMT_R_PdlAlys_Cyclic_10ms: start-on-event=R_PdlAlys_Cyclic_10ms, period=0.01
      init event CtAp_PdlAlys_InitEvent: start-on-event=R_PdlAlys_Init
      runnable R_PdlAlys_Cyclic_10ms
        data-receive-point-by-arguments:
          9 x access:
            REC_RTE_R_ComM_IBSBrkMstCylPrs_pct_tec_ComM_IBSBrkMstCylPrs_pct: accessed-variable=RTE_R_ComM_IBSBrkMstCylPrs_pct.tec_ComM_IBSBrkMstCylPrs_pct
            REC_RTE_R_ComM_IBSBrkPlgrPrs_pct_tec_ComM_IBSBrkPlgrPrs_pct: accessed-variable=RTE_R_ComM_IBSBrkPlgrPrs_pct.tec_ComM_IBSBrkPlgrPrs_pct
            REC_RTE_R_ComM_IBSBrkSts_Enum_tec_ComM_IBSBrkSts_Enum: accessed-variable=RTE_R_ComM_IBSBrkSts_Enum.tec_ComM_IBSBrkSts_Enum
            REC_RTE_R_ErrMgmt_ComFailDTC_16bit_tec_ErrMgmt_ComFailDTC_16bit: accessed-variable=RTE_R_ErrMgmt_ComFailDTC_16bit.tec_ErrMgmt_ComFailDTC_16bit
            REC_RTE_R_IOAbs_AccrPedlMaiRaw_mV_tec_IOAbs_AccrPedlMaiRaw_mV: accessed-variable=RTE_R_IOAbs_AccrPedlMaiRaw_mV.tec_IOAbs_AccrPedlMaiRaw_mV
            REC_RTE_R_IOAbs_AccrPedlRdnRaw_mV_tec_IOAbs_AccrPedlRdnRaw_mV: accessed-variable=RTE_R_IOAbs_AccrPedlRdnRaw_mV.tec_IOAbs_AccrPedlRdnRaw_mV
            REC_RTE_R_IOAbs_BrkMaiRaw_Flg_tec_IOAbs_BrkMaiRaw_Flg: accessed-variable=RTE_R_IOAbs_BrkMaiRaw_Flg.tec_IOAbs_BrkMaiRaw_Flg
            REC_RTE_R_IOAbs_BrkRdnRaw_Flg_tec_IOAbs_BrkRdnRaw_Flg: accessed-variable=RTE_R_IOAbs_BrkRdnRaw_Flg.tec_IOAbs_BrkRdnRaw_Flg
            REC_RTE_R_LvMgmt_WakeUpSrc_Enum_tec_LvMgmt_WakeUpSrc_Enum: accessed-variable=RTE_R_LvMgmt_WakeUpSrc_Enum.tec_LvMgmt_WakeUpSrc_Enum
        data-send-points:
          9 x access:
            SEND_RTE_P_ChassisMgmt_AccrPedlFltSts_Enum_tec_ChassisMgmt_AccrPedlFltSts_Enum: accessed-variable=RTE_P_ChassisMgmt_AccrPedlFltSts_Enum.tec_ChassisMgmt_AccrPedlFltSts_Enum
            SEND_RTE_P_ChassisMgmt_AccrPedlPosn_pct_tec_ChassisMgmt_AccrPedlPosn_pct: accessed-variable=RTE_P_ChassisMgmt_AccrPedlPosn_pct.tec_ChassisMgmt_AccrPedlPosn_pct
            SEND_RTE_P_ChassisMgmt_AccrPedlPosnRaw_pct_tec_ChassisMgmt_AccrPedlPosnRaw_pct: accessed-variable=RTE_P_ChassisMgmt_AccrPedlPosnRaw_pct.tec_ChassisMgmt_AccrPedlPosnRaw_pct
            SEND_RTE_P_ChassisMgmt_AccrPedlVld_Flg_tec_ChassisMgmt_AccrPedlVld_Flg: accessed-variable=RTE_P_ChassisMgmt_AccrPedlVld_Flg.tec_ChassisMgmt_AccrPedlVld_Flg
            SEND_RTE_P_ChassisMgmt_BrkFltSts_Flg_tec_ChassisMgmt_BrkFltSts_Flg: accessed-variable=RTE_P_ChassisMgmt_BrkFltSts_Flg.tec_ChassisMgmt_BrkFltSts_Flg
            SEND_RTE_P_ChassisMgmt_BrkPedlPosn_pct_tec_ChassisMgmt_BrkPedlPosn_pct: accessed-variable=RTE_P_ChassisMgmt_BrkPedlPosn_pct.tec_ChassisMgmt_BrkPedlPosn_pct
            SEND_RTE_P_ChassisMgmt_BrkSts_Flg_tec_ChassisMgmt_BrkSts_Flg: accessed-variable=RTE_P_ChassisMgmt_BrkSts_Flg.tec_ChassisMgmt_BrkSts_Flg
            SEND_RTE_P_ChassisMgmt_BrkStsVld_Flg_tec_ChassisMgmt_BrkStsVld_Flg: accessed-variable=RTE_P_ChassisMgmt_BrkStsVld_Flg.tec_ChassisMgmt_BrkStsVld_Flg
            SEND_RTE_P_ChassisMgmt_PedlAlysDTC_16bit_tec_ChassisMgmt_PedlAlysDTC_16bit: accessed-variable=RTE_P_ChassisMgmt_PedlAlysDTC_16bit.tec_ChassisMgmt_PedlAlysDTC_16bit
      runnable R_PdlAlys_Init
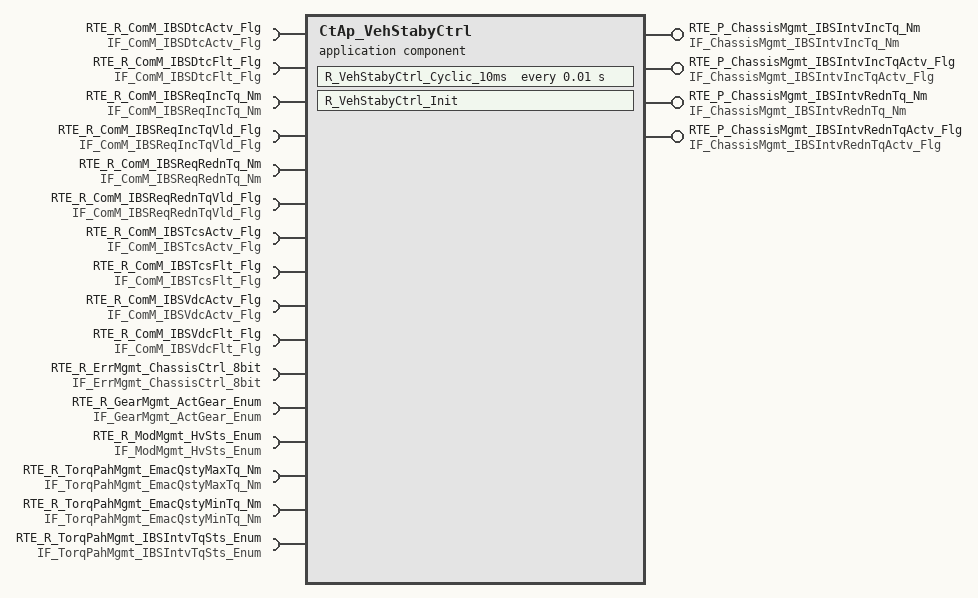
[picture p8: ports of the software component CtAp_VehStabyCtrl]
  application sw component type CtAp_VehStabyCtrl
    4 x provide port:
      RTE_P_ChassisMgmt_IBSIntvIncTq_Nm: nonqueued-sender-com-spec{data-element=tec_ChassisMgmt_IBSIntvIncTq_Nm, init-value=0}, provided-interface=IF_ChassisMgmt_IBSIntvIncTq_Nm
      RTE_P_ChassisMgmt_IBSIntvIncTqActv_Flg: nonqueued-sender-com-spec{data-element=tec_ChassisMgmt_IBSIntvIncTqActv_Flg, init-value=0}, provided-interface=IF_ChassisMgmt_IBSIntvIncTqActv_Flg
      RTE_P_ChassisMgmt_IBSIntvRednTq_Nm: nonqueued-sender-com-spec{data-element=tec_ChassisMgmt_IBSIntvRednTq_Nm, init-value=0}, provided-interface=IF_ChassisMgmt_IBSIntvRednTq_Nm
      RTE_P_ChassisMgmt_IBSIntvRednTqActv_Flg: nonqueued-sender-com-spec{data-element=tec_ChassisMgmt_IBSIntvRednTqActv_Flg, init-value=0}, provided-interface=IF_ChassisMgmt_IBSIntvRednTqActv_Flg
    16 x require port:
      RTE_R_ComM_IBSDtcActv_Flg: nonqueued-receiver-com-spec{data-element=tec_ComM_IBSDtcActv_Flg, filter=data-filter-type=ALWAYS, init-value=0}, required-interface=IF_ComM_IBSDtcActv_Flg
      RTE_R_ComM_IBSDtcFlt_Flg: nonqueued-receiver-com-spec{data-element=tec_ComM_IBSDtcFlt_Flg, filter=data-filter-type=ALWAYS, init-value=0}, required-interface=IF_ComM_IBSDtcFlt_Flg
      RTE_R_ComM_IBSReqIncTq_Nm: nonqueued-receiver-com-spec{data-element=tec_ComM_IBSReqIncTq_Nm, filter=data-filter-type=ALWAYS, init-value=0}, required-interface=IF_ComM_IBSReqIncTq_Nm
      RTE_R_ComM_IBSReqIncTqVld_Flg: nonqueued-receiver-com-spec{data-element=tec_ComM_IBSReqIncTqVld_Flg, filter=data-filter-type=ALWAYS, init-value=0}, required-interface=IF_ComM_IBSReqIncTqVld_Flg
      RTE_R_ComM_IBSReqRednTq_Nm: nonqueued-receiver-com-spec{data-element=tec_ComM_IBSReqRednTq_Nm, filter=data-filter-type=ALWAYS, init-value=0}, required-interface=IF_ComM_IBSReqRednTq_Nm
      RTE_R_ComM_IBSReqRednTqVld_Flg: nonqueued-receiver-com-spec{data-element=tec_ComM_IBSReqRednTqVld_Flg, filter=data-filter-type=ALWAYS, init-value=0}, required-interface=IF_ComM_IBSReqRednTqVld_Flg
      RTE_R_ComM_IBSTcsActv_Flg: nonqueued-receiver-com-spec{data-element=tec_ComM_IBSTcsActv_Flg, filter=data-filter-type=ALWAYS, init-value=0}, required-interface=IF_ComM_IBSTcsActv_Flg
      RTE_R_ComM_IBSTcsFlt_Flg: nonqueued-receiver-com-spec{data-element=tec_ComM_IBSTcsFlt_Flg, filter=data-filter-type=ALWAYS, init-value=0}, required-interface=IF_ComM_IBSTcsFlt_Flg
      RTE_R_ComM_IBSVdcActv_Flg: nonqueued-receiver-com-spec{data-element=tec_ComM_IBSVdcActv_Flg, filter=data-filter-type=ALWAYS, init-value=0}, required-interface=IF_ComM_IBSVdcActv_Flg
      RTE_R_ComM_IBSVdcFlt_Flg: nonqueued-receiver-com-spec{data-element=tec_ComM_IBSVdcFlt_Flg, filter=data-filter-type=ALWAYS, init-value=0}, required-interface=IF_ComM_IBSVdcFlt_Flg
      RTE_R_ErrMgmt_ChassisCtrl_8bit: nonqueued-receiver-com-spec{data-element=tec_ErrMgmt_ChassisCtrl_8bit, filter=data-filter-type=ALWAYS, init-value=0}, required-interface=IF_ErrMgmt_ChassisCtrl_8bit
      RTE_R_GearMgmt_ActGear_Enum: nonqueued-receiver-com-spec{data-element=tec_GearMgmt_ActGear_Enum, filter=data-filter-type=ALWAYS, init-value=0}, required-interface=IF_GearMgmt_ActGear_Enum
      RTE_R_ModMgmt_HvSts_Enum: nonqueued-receiver-com-spec{data-element=tec_ModMgmt_HvSts_Enum, filter=data-filter-type=ALWAYS, init-value=0}, required-interface=IF_ModMgmt_HvSts_Enum
      RTE_R_TorqPahMgmt_EmacQstyMaxTq_Nm: nonqueued-receiver-com-spec{data-element=tec_TorqPahMgmt_EmacQstyMaxTq_Nm, filter=data-filter-type=ALWAYS, init-value=0}, required-interface=IF_TorqPahMgmt_EmacQstyMaxTq_Nm
      RTE_R_TorqPahMgmt_EmacQstyMinTq_Nm: nonqueued-receiver-com-spec{data-element=tec_TorqPahMgmt_EmacQstyMinTq_Nm, filter=data-filter-type=ALWAYS, init-value=0}, required-interface=IF_TorqPahMgmt_EmacQstyMinTq_Nm
      RTE_R_TorqPahMgmt_IBSIntvTqSts_Enum: nonqueued-receiver-com-spec{data-element=tec_TorqPahMgmt_IBSIntvTqSts_Enum, filter=data-filter-type=ALWAYS, init-value=0}, required-interface=IF_TorqPahMgmt_IBSIntvTqSts_Enum
    behavior CtAp_VehStabyCtrl_InternalBehavior
      timing event TMT_R_VehStabyCtrl_Cyclic_10ms: start-on-event=R_VehStabyCtrl_Cyclic_10ms, period=0.01
      init event CtAp_VehStabyCtrl_InitEvent: start-on-event=R_VehStabyCtrl_Init
      runnable R_VehStabyCtrl_Cyclic_10ms
        data-receive-point-by-arguments:
          16 x access:
            REC_RTE_R_ComM_IBSDtcActv_Flg_tec_ComM_IBSDtcActv_Flg: accessed-variable=RTE_R_ComM_IBSDtcActv_Flg.tec_ComM_IBSDtcActv_Flg
            REC_RTE_R_ComM_IBSDtcFlt_Flg_tec_ComM_IBSDtcFlt_Flg: accessed-variable=RTE_R_ComM_IBSDtcFlt_Flg.tec_ComM_IBSDtcFlt_Flg
            REC_RTE_R_Comm_IBSReqIncTq_Nm_tec_ComM_IBSReqIncTq_Nm: accessed-variable=RTE_R_ComM_IBSReqIncTq_Nm.tec_ComM_IBSReqIncTq_Nm
            REC_RTE_R_Comm_IBSReqIncTqVld_Flg_tec_ComM_IBSReqIncTqVld_Flg: accessed-variable=RTE_R_ComM_IBSReqIncTqVld_Flg.tec_ComM_IBSReqIncTqVld_Flg
            REC_RTE_R_Comm_IBSReqRednTq_Nm_tec_ComM_IBSReqRednTq_Nm: accessed-variable=RTE_R_ComM_IBSReqRednTq_Nm.tec_ComM_IBSReqRednTq_Nm
            REC_RTE_R_Comm_IBSReqRednTqVld_Flg_tec_ComM_IBSReqRednTqVld_Flg: accessed-variable=RTE_R_ComM_IBSReqRednTqVld_Flg.tec_ComM_IBSReqRednTqVld_Flg
            REC_RTE_R_ComM_IBSTcsActv_Flg_tec_ComM_IBSTcsActv_Flg: accessed-variable=RTE_R_ComM_IBSTcsActv_Flg.tec_ComM_IBSTcsActv_Flg
            REC_RTE_R_ComM_IBSTcsFlt_Flg_tec_ComM_IBSTcsFlt_Flg: accessed-variable=RTE_R_ComM_IBSTcsFlt_Flg.tec_ComM_IBSTcsFlt_Flg
            REC_RTE_R_ComM_IBSVdcActv_Flg_tec_ComM_IBSVdcActv_Flg: accessed-variable=RTE_R_ComM_IBSVdcActv_Flg.tec_ComM_IBSVdcActv_Flg
            REC_RTE_R_ComM_IBSVdcFlt_Flg_tec_ComM_IBSVdcFlt_Flg: accessed-variable=RTE_R_ComM_IBSVdcFlt_Flg.tec_ComM_IBSVdcFlt_Flg
            REC_RTE_R_ErrMgmt_ChassisCtrl_8bit_tec_ErrMgmt_ChassisCtrl_8bit: accessed-variable=RTE_R_ErrMgmt_ChassisCtrl_8bit.tec_ErrMgmt_ChassisCtrl_8bit
            REC_RTE_R_GearMgmt_ActGear_Enum_tec_GearMgmt_ActGear_Enum: accessed-variable=RTE_R_GearMgmt_ActGear_Enum.tec_GearMgmt_ActGear_Enum
            REC_RTE_R_ModMgmt_HvSts_Enum_tec_ModMgmt_HvSts_Enum: accessed-variable=RTE_R_ModMgmt_HvSts_Enum.tec_ModMgmt_HvSts_Enum
            REC_RTE_R_TorqPahMgmt_EmacQstyMaxTq_Nm_tec_TorqPahMgmt_EmacQstyMaxTq_Nm: accessed-variable=RTE_R_TorqPahMgmt_EmacQstyMaxTq_Nm.tec_TorqPahMgmt_EmacQstyMaxTq_Nm
            REC_RTE_R_TorqPahMgmt_EmacQstyMinTq_Nm_tec_TorqPahMgmt_EmacQstyMinTq_Nm: accessed-variable=RTE_R_TorqPahMgmt_EmacQstyMinTq_Nm.tec_TorqPahMgmt_EmacQstyMinTq_Nm
            REC_RTE_R_TorqPahMgmt_IBSIntvTqSts_Enum_tec_TorqPahMgmt_IBSIntvTqSts_Enum: accessed-variable=RTE_R_TorqPahMgmt_IBSIntvTqSts_Enum.tec_TorqPahMgmt_IBSIntvTqSts_Enum
        data-send-points:
          4 x access:
            SEND_RTE_P_ChassisMgmt_IBSIntvIncTq_Nm_tec_ChassisMgmt_IBSIntvIncTq_Nm: accessed-variable=RTE_P_ChassisMgmt_IBSIntvIncTq_Nm.tec_ChassisMgmt_IBSIntvIncTq_Nm
            SEND_RTE_P_ChassisMgmt_IBSIntvIncTqActv_Flg_tec_ChassisMgmt_IBSIntvIncTqActv_Flg: accessed-variable=RTE_P_ChassisMgmt_IBSIntvIncTqActv_Flg.tec_ChassisMgmt_IBSIntvIncTqActv_Flg
            SEND_RTE_P_ChassisMgmt_IBSIntvRednTq_Nm_tec_ChassisMgmt_IBSIntvRednTq_Nm: accessed-variable=RTE_P_ChassisMgmt_IBSIntvRednTq_Nm.tec_ChassisMgmt_IBSIntvRednTq_Nm
            SEND_RTE_P_ChassisMgmt_IBSIntvRednTqActv_Flg_tec_ChassisMgmt_IBSIntvRednTqActv_Flg: accessed-variable=RTE_P_ChassisMgmt_IBSIntvRednTqActv_Flg.tec_ChassisMgmt_IBSIntvRednTqActv_Flg
      runnable R_VehStabyCtrl_Init
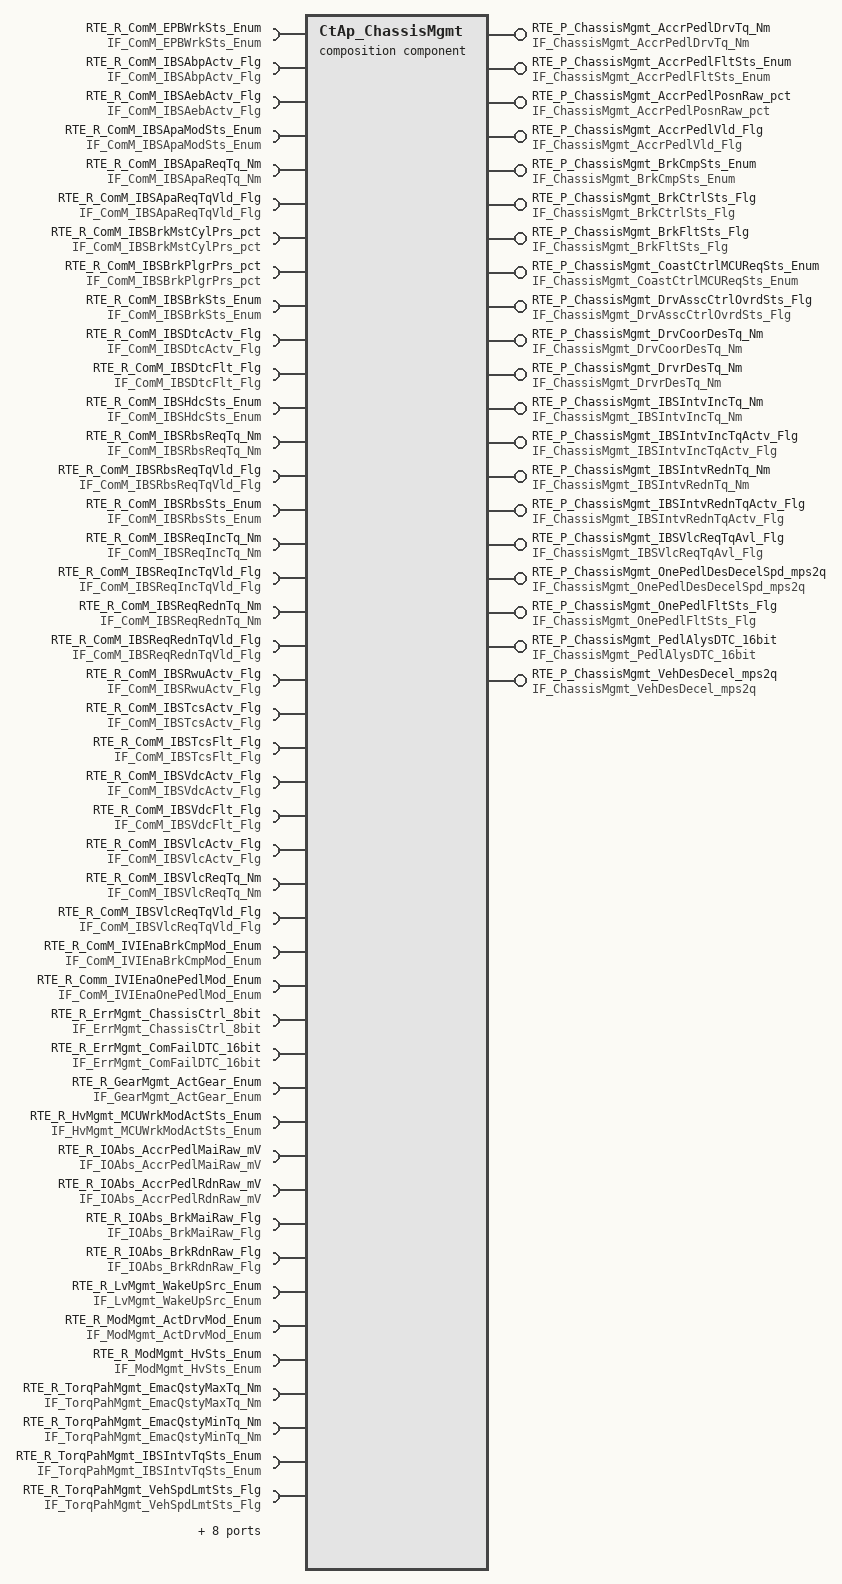
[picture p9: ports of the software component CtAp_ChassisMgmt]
  composition sw component type CtAp_ChassisMgmt
    20 x provide port:
      RTE_P_ChassisMgmt_AccrPedlDrvTq_Nm: nonqueued-sender-com-spec{data-element=tec_ChassisMgmt_AccrPedlDrvTq_Nm, init-value=0}, provided-interface=IF_ChassisMgmt_AccrPedlDrvTq_Nm
      RTE_P_ChassisMgmt_AccrPedlFltSts_Enum: nonqueued-sender-com-spec{data-element=tec_ChassisMgmt_AccrPedlFltSts_Enum, init-value=0}, provided-interface=IF_ChassisMgmt_AccrPedlFltSts_Enum
      RTE_P_ChassisMgmt_AccrPedlPosnRaw_pct: nonqueued-sender-com-spec{data-element=tec_ChassisMgmt_AccrPedlPosnRaw_pct, init-value=0}, provided-interface=IF_ChassisMgmt_AccrPedlPosnRaw_pct
      RTE_P_ChassisMgmt_AccrPedlVld_Flg: nonqueued-sender-com-spec{data-element=tec_ChassisMgmt_AccrPedlVld_Flg, init-value=0}, provided-interface=IF_ChassisMgmt_AccrPedlVld_Flg
      RTE_P_ChassisMgmt_BrkCmpSts_Enum: nonqueued-sender-com-spec{data-element=tec_ChassisMgmt_BrkCmpSts_Enum, init-value=0}, provided-interface=IF_ChassisMgmt_BrkCmpSts_Enum
      RTE_P_ChassisMgmt_BrkCtrlSts_Flg: nonqueued-sender-com-spec{data-element=tec_ChassisMgmt_BrkCtrlSts_Flg, init-value=0}, provided-interface=IF_ChassisMgmt_BrkCtrlSts_Flg
      RTE_P_ChassisMgmt_BrkFltSts_Flg: nonqueued-sender-com-spec{data-element=tec_ChassisMgmt_BrkFltSts_Flg, init-value=0}, provided-interface=IF_ChassisMgmt_BrkFltSts_Flg
      RTE_P_ChassisMgmt_CoastCtrlMCUReqSts_Enum: nonqueued-sender-com-spec{data-element=tec_ChassisMgmt_CoastCtrlMCUReqSts_Enum, init-value=0}, provided-interface=IF_ChassisMgmt_CoastCtrlMCUReqSts_Enum
      RTE_P_ChassisMgmt_DrvAsscCtrlOvrdSts_Flg: nonqueued-sender-com-spec{data-element=tec_ChassisMgmt_DrvAsscCtrlOvrdSts_Flg, init-value=0}, provided-interface=IF_ChassisMgmt_DrvAsscCtrlOvrdSts_Flg
      RTE_P_ChassisMgmt_DrvCoorDesTq_Nm: nonqueued-sender-com-spec{data-element=tec_ChassisMgmt_DrvCoorDesTq_Nm, init-value=0}, provided-interface=IF_ChassisMgmt_DrvCoorDesTq_Nm
      RTE_P_ChassisMgmt_DrvrDesTq_Nm: nonqueued-sender-com-spec{data-element=tec_ChassisMgmt_DrvrDesTq_Nm, init-value=0}, provided-interface=IF_ChassisMgmt_DrvrDesTq_Nm
      RTE_P_ChassisMgmt_IBSIntvIncTq_Nm: nonqueued-sender-com-spec{data-element=tec_ChassisMgmt_IBSIntvIncTq_Nm, init-value=0}, provided-interface=IF_ChassisMgmt_IBSIntvIncTq_Nm
      RTE_P_ChassisMgmt_IBSIntvIncTqActv_Flg: nonqueued-sender-com-spec{data-element=tec_ChassisMgmt_IBSIntvIncTqActv_Flg, init-value=0}, provided-interface=IF_ChassisMgmt_IBSIntvIncTqActv_Flg
      RTE_P_ChassisMgmt_IBSIntvRednTq_Nm: nonqueued-sender-com-spec{data-element=tec_ChassisMgmt_IBSIntvRednTq_Nm, init-value=0}, provided-interface=IF_ChassisMgmt_IBSIntvRednTq_Nm
      RTE_P_ChassisMgmt_IBSIntvRednTqActv_Flg: nonqueued-sender-com-spec{data-element=tec_ChassisMgmt_IBSIntvRednTqActv_Flg, init-value=0}, provided-interface=IF_ChassisMgmt_IBSIntvRednTqActv_Flg
      RTE_P_ChassisMgmt_IBSVlcReqTqAvl_Flg: nonqueued-sender-com-spec{data-element=tec_ChassisMgmt_IBSVlcReqTqAvl_Flg, init-value=0}, provided-interface=IF_ChassisMgmt_IBSVlcReqTqAvl_Flg
      RTE_P_ChassisMgmt_OnePedlDesDecelSpd_mps2q: nonqueued-sender-com-spec{data-element=tec_ChassisMgmt_OnePedlDesDecelSpd_mps2q, init-value=0}, provided-interface=IF_ChassisMgmt_OnePedlDesDecelSpd_mps2q
      RTE_P_ChassisMgmt_OnePedlFltSts_Flg: nonqueued-sender-com-spec{data-element=tec_ChassisMgmt_OnePedlFltSts_Flg, init-value=0}, provided-interface=IF_ChassisMgmt_OnePedlFltSts_Flg
      RTE_P_ChassisMgmt_PedlAlysDTC_16bit: nonqueued-sender-com-spec{data-element=tec_ChassisMgmt_PedlAlysDTC_16bit, init-value=0}, provided-interface=IF_ChassisMgmt_PedlAlysDTC_16bit
      RTE_P_ChassisMgmt_VehDesDecel_mps2q: nonqueued-sender-com-spec{data-element=tec_ChassisMgmt_BrkCmpDesDecel_mps2q, init-value=0}, provided-interface=IF_ChassisMgmt_VehDesDecel_mps2q
    52 x require port:
      RTE_R_ComM_EPBWrkSts_Enum: nonqueued-receiver-com-spec{data-element=tec_ComM_EPBWrkSts_Enum, filter=data-filter-type=ALWAYS, init-value=0}, required-interface=IF_ComM_EPBWrkSts_Enum
      RTE_R_ComM_IBSAbpActv_Flg: nonqueued-receiver-com-spec{data-element=tec_ComM_IBSAbpActv_Flg, filter=data-filter-type=ALWAYS, init-value=0}, required-interface=IF_ComM_IBSAbpActv_Flg
      RTE_R_ComM_IBSAebActv_Flg: nonqueued-receiver-com-spec{data-element=tec_ComM_IBSAebActv_Flg, filter=data-filter-type=ALWAYS, init-value=0}, required-interface=IF_ComM_IBSAebActv_Flg
      RTE_R_ComM_IBSApaModSts_Enum: nonqueued-receiver-com-spec{data-element=tec_ComM_IBSApaModSts_Enum, filter=data-filter-type=ALWAYS, init-value=0}, required-interface=IF_ComM_IBSApaModSts_Enum
      RTE_R_ComM_IBSApaReqTq_Nm: nonqueued-receiver-com-spec{data-element=tec_ComM_IBSApaReqTq_Nm, filter=data-filter-type=ALWAYS, init-value=0}, required-interface=IF_ComM_IBSApaReqTq_Nm
      RTE_R_ComM_IBSApaReqTqVld_Flg: nonqueued-receiver-com-spec{data-element=tec_ComM_IBSApaReqTqVld_Flg, filter=data-filter-type=ALWAYS, init-value=0}, required-interface=IF_ComM_IBSApaReqTqVld_Flg
      RTE_R_ComM_IBSBrkMstCylPrs_pct: nonqueued-receiver-com-spec{data-element=tec_ComM_IBSBrkMstCylPrs_pct, filter=data-filter-type=ALWAYS, init-value=0}, required-interface=IF_ComM_IBSBrkMstCylPrs_pct
      RTE_R_ComM_IBSBrkPlgrPrs_pct: nonqueued-receiver-com-spec{data-element=tec_ComM_IBSBrkPlgrPrs_pct, filter=data-filter-type=ALWAYS, init-value=0}, required-interface=IF_ComM_IBSBrkPlgrPrs_pct
      RTE_R_ComM_IBSBrkSts_Enum: nonqueued-receiver-com-spec{data-element=tec_ComM_IBSBrkSts_Enum, filter=data-filter-type=ALWAYS, init-value=0}, required-interface=IF_ComM_IBSBrkSts_Enum
      RTE_R_ComM_IBSDtcActv_Flg: nonqueued-receiver-com-spec{data-element=tec_ComM_IBSDtcActv_Flg, filter=data-filter-type=ALWAYS, init-value=0}, required-interface=IF_ComM_IBSDtcActv_Flg
      RTE_R_ComM_IBSDtcFlt_Flg: nonqueued-receiver-com-spec{data-element=tec_ComM_IBSDtcFlt_Flg, filter=data-filter-type=ALWAYS, init-value=0}, required-interface=IF_ComM_IBSDtcFlt_Flg
      RTE_R_ComM_IBSHdcSts_Enum: nonqueued-receiver-com-spec{data-element=tec_ComM_IBSHdcSts_Enum, filter=data-filter-type=ALWAYS, init-value=0}, required-interface=IF_ComM_IBSHdcSts_Enum
      RTE_R_ComM_IBSRbsReqTq_Nm: nonqueued-receiver-com-spec{data-element=tec_ComM_IBSRbsReqTq_Nm, filter=data-filter-type=ALWAYS, init-value=0}, required-interface=IF_ComM_IBSRbsReqTq_Nm
      RTE_R_ComM_IBSRbsReqTqVld_Flg: nonqueued-receiver-com-spec{data-element=tec_ComM_IBSRbsReqTqVld_Flg, filter=data-filter-type=ALWAYS, init-value=0}, required-interface=IF_ComM_IBSRbsReqTqVld_Flg
      RTE_R_ComM_IBSRbsSts_Enum: nonqueued-receiver-com-spec{data-element=tec_ComM_IBSRbsSts_Enum, filter=data-filter-type=ALWAYS, init-value=0}, required-interface=IF_ComM_IBSRbsSts_Enum
      RTE_R_ComM_IBSReqIncTq_Nm: nonqueued-receiver-com-spec{data-element=tec_ComM_IBSReqIncTq_Nm, filter=data-filter-type=ALWAYS, init-value=0}, required-interface=IF_ComM_IBSReqIncTq_Nm
      RTE_R_ComM_IBSReqIncTqVld_Flg: nonqueued-receiver-com-spec{data-element=tec_ComM_IBSReqIncTqVld_Flg, filter=data-filter-type=ALWAYS, init-value=0}, required-interface=IF_ComM_IBSReqIncTqVld_Flg
      RTE_R_ComM_IBSReqRednTq_Nm: nonqueued-receiver-com-spec{data-element=tec_ComM_IBSReqRednTq_Nm, filter=data-filter-type=ALWAYS, init-value=0}, required-interface=IF_ComM_IBSReqRednTq_Nm
      RTE_R_ComM_IBSReqRednTqVld_Flg: nonqueued-receiver-com-spec{data-element=tec_ComM_IBSReqRednTqVld_Flg, filter=data-filter-type=ALWAYS, init-value=0}, required-interface=IF_ComM_IBSReqRednTqVld_Flg
      RTE_R_ComM_IBSRwuActv_Flg: nonqueued-receiver-com-spec{data-element=tec_ComM_IBSRwuActv_Flg, filter=data-filter-type=ALWAYS, init-value=0}, required-interface=IF_ComM_IBSRwuActv_Flg
      RTE_R_ComM_IBSTcsActv_Flg: nonqueued-receiver-com-spec{data-element=tec_ComM_IBSTcsActv_Flg, filter=data-filter-type=ALWAYS, init-value=0}, required-interface=IF_ComM_IBSTcsActv_Flg
      RTE_R_ComM_IBSTcsFlt_Flg: nonqueued-receiver-com-spec{data-element=tec_ComM_IBSTcsFlt_Flg, filter=data-filter-type=ALWAYS, init-value=0}, required-interface=IF_ComM_IBSTcsFlt_Flg
      RTE_R_ComM_IBSVdcActv_Flg: nonqueued-receiver-com-spec{data-element=tec_ComM_IBSVdcActv_Flg, filter=data-filter-type=ALWAYS, init-value=0}, required-interface=IF_ComM_IBSVdcActv_Flg
      RTE_R_ComM_IBSVdcFlt_Flg: nonqueued-receiver-com-spec{data-element=tec_ComM_IBSVdcFlt_Flg, filter=data-filter-type=ALWAYS, init-value=0}, required-interface=IF_ComM_IBSVdcFlt_Flg
      RTE_R_ComM_IBSVlcActv_Flg: nonqueued-receiver-com-spec{data-element=tec_ComM_IBSVlcActv_Flg, filter=data-filter-type=ALWAYS, init-value=0}, required-interface=IF_ComM_IBSVlcActv_Flg
      RTE_R_ComM_IBSVlcReqTq_Nm: nonqueued-receiver-com-spec{data-element=tec_ComM_IBSVlcReqTq_Nm, filter=data-filter-type=ALWAYS, init-value=0}, required-interface=IF_ComM_IBSVlcReqTq_Nm
      RTE_R_ComM_IBSVlcReqTqVld_Flg: nonqueued-receiver-com-spec{data-element=tec_ComM_IBSVlcReqTqVld_Flg, filter=data-filter-type=ALWAYS, init-value=0}, required-interface=IF_ComM_IBSVlcReqTqVld_Flg
      RTE_R_ComM_IVIEnaBrkCmpMod_Enum: nonqueued-receiver-com-spec{data-element=tec_ComM_IVIEnaBrkCmpMod_Enum, filter=data-filter-type=ALWAYS, init-value=0}, required-interface=IF_ComM_IVIEnaBrkCmpMod_Enum
      RTE_R_Comm_IVIEnaOnePedlMod_Enum: nonqueued-receiver-com-spec{data-element=tec_ComM_IVIEnaOnePedlMod_Enum, filter=data-filter-type=ALWAYS, init-value=0}, required-interface=IF_ComM_IVIEnaOnePedlMod_Enum
      RTE_R_ErrMgmt_ChassisCtrl_8bit: nonqueued-receiver-com-spec{data-element=tec_ErrMgmt_ChassisCtrl_8bit, filter=data-filter-type=ALWAYS, init-value=0}, required-interface=IF_ErrMgmt_ChassisCtrl_8bit
      RTE_R_ErrMgmt_ComFailDTC_16bit: nonqueued-receiver-com-spec{data-element=tec_ErrMgmt_ComFailDTC_16bit, filter=data-filter-type=ALWAYS, init-value=0}, required-interface=IF_ErrMgmt_ComFailDTC_16bit
      RTE_R_GearMgmt_ActGear_Enum: nonqueued-receiver-com-spec{data-element=tec_GearMgmt_ActGear_Enum, filter=data-filter-type=ALWAYS, init-value=0}, required-interface=IF_GearMgmt_ActGear_Enum
      RTE_R_HvMgmt_MCUWrkModActSts_Enum: nonqueued-receiver-com-spec{data-element=tec_HvMgmt_MCUWrkModActSts_Enum, filter=data-filter-type=ALWAYS, init-value=0}, required-interface=IF_HvMgmt_MCUWrkModActSts_Enum
      RTE_R_IOAbs_AccrPedlMaiRaw_mV: nonqueued-receiver-com-spec{data-element=tec_IOAbs_AccrPedlMaiRaw_mV, filter=data-filter-type=ALWAYS, init-value=0}, required-interface=IF_IOAbs_AccrPedlMaiRaw_mV
      RTE_R_IOAbs_AccrPedlRdnRaw_mV: nonqueued-receiver-com-spec{data-element=tec_IOAbs_AccrPedlRdnRaw_mV, filter=data-filter-type=ALWAYS, init-value=0}, required-interface=IF_IOAbs_AccrPedlRdnRaw_mV
      RTE_R_IOAbs_BrkMaiRaw_Flg: nonqueued-receiver-com-spec{data-element=tec_IOAbs_BrkMaiRaw_Flg, filter=data-filter-type=ALWAYS, init-value=0}, required-interface=IF_IOAbs_BrkMaiRaw_Flg
      RTE_R_IOAbs_BrkRdnRaw_Flg: nonqueued-receiver-com-spec{data-element=tec_IOAbs_BrkRdnRaw_Flg, filter=data-filter-type=ALWAYS, init-value=0}, required-interface=IF_IOAbs_BrkRdnRaw_Flg
      RTE_R_LvMgmt_WakeUpSrc_Enum: nonqueued-receiver-com-spec{data-element=tec_LvMgmt_WakeUpSrc_Enum, filter=data-filter-type=ALWAYS, init-value=0}, required-interface=IF_LvMgmt_WakeUpSrc_Enum
      RTE_R_ModMgmt_ActDrvMod_Enum: nonqueued-receiver-com-spec{data-element=tec_ModMgmt_ActDrvMod_Enum, filter=data-filter-type=ALWAYS, init-value=0}, required-interface=IF_ModMgmt_ActDrvMod_Enum
      RTE_R_ModMgmt_HvSts_Enum: nonqueued-receiver-com-spec{data-element=tec_ModMgmt_HvSts_Enum, filter=data-filter-type=ALWAYS, init-value=0}, required-interface=IF_ModMgmt_HvSts_Enum
      RTE_R_TorqPahMgmt_EmacQstyMaxTq_Nm: nonqueued-receiver-com-spec{data-element=tec_TorqPahMgmt_EmacQstyMaxTq_Nm, filter=data-filter-type=ALWAYS, init-value=0}, required-interface=IF_TorqPahMgmt_EmacQstyMaxTq_Nm
      RTE_R_TorqPahMgmt_EmacQstyMinTq_Nm: nonqueued-receiver-com-spec{data-element=tec_TorqPahMgmt_EmacQstyMinTq_Nm, filter=data-filter-type=ALWAYS, init-value=0}, required-interface=IF_TorqPahMgmt_EmacQstyMinTq_Nm
      RTE_R_TorqPahMgmt_IBSIntvTqSts_Enum: nonqueued-receiver-com-spec{data-element=tec_TorqPahMgmt_IBSIntvTqSts_Enum, filter=data-filter-type=ALWAYS, init-value=0}, required-interface=IF_TorqPahMgmt_IBSIntvTqSts_Enum
      RTE_R_TorqPahMgmt_VehSpdLmtSts_Flg: nonqueued-receiver-com-spec{data-element=tec_TorqPahMgmt_VehSpdLmtSts_Flg, filter=data-filter-type=ALWAYS, init-value=0}, required-interface=IF_TorqPahMgmt_VehSpdLmtSts_Flg
      RTE_R_TorqPahMgmt_VehSpdLmtTq_Nm: nonqueued-receiver-com-spec{data-element=tec_TorqPahMgmt_VehSpdLmtTq_Nm, filter=data-filter-type=ALWAYS, init-value=0}, required-interface=IF_TorqPahMgmt_VehSpdLmtTq_Nm
      RTE_R_VehMot_Acclr2Tq_Nm: nonqueued-receiver-com-spec{data-element=tec_VehMot_Acclr2Tq_Nm, filter=data-filter-type=ALWAYS, init-value=0}, required-interface=IF_VehMot_Acclr2Tq_Nm
      RTE_R_VehMot_AcclrPrpCurr_mps2q: nonqueued-receiver-com-spec{data-element=tec_VehMot_AcclrPrpCurr_mps2q, filter=data-filter-type=ALWAYS, init-value=0}, required-interface=IF_VehMot_AcclrPrpCurr_mps2q
      RTE_R_VehMot_SlopGrd_deg: nonqueued-receiver-com-spec{data-element=tec_VehMot_SlopGrd_deg, filter=data-filter-type=ALWAYS, init-value=0}, required-interface=IF_VehMot_SlopGrd_deg
      RTE_R_VehMot_VehDirDif_Flg: nonqueued-receiver-com-spec{data-element=tec_VehMot_VehDirDif_Flg, filter=data-filter-type=ALWAYS, init-value=0}, required-interface=IF_VehMot_VehDirDif_Flg
      RTE_R_VehMot_VehDragTq_Nm: nonqueued-receiver-com-spec{data-element=tec_VehMot_VehDragTq_Nm, filter=data-filter-type=ALWAYS, init-value=0}, required-interface=IF_VehMot_VehDragTq_Nm
      RTE_R_VehMot_VehSpd_kph: nonqueued-receiver-com-spec{data-element=tec_VehMot_VehSpd_kph, filter=data-filter-type=ALWAYS, init-value=0}, required-interface=IF_VehMot_VehSpd_kph
      RTE_R_VehMot_VehSpdVld_Flg: nonqueued-receiver-com-spec{data-element=tec_VehMot_VehSpdVld_Flg, filter=data-filter-type=ALWAYS, init-value=0}, required-interface=IF_VehMot_VehSpdVld_Flg
    9 x component:
      CtAp_AccrPedlDrv: type=CtAp_AccrPedlDrv
      CtAp_BrkMgmt: type=CtAp_BrkMgmt
      CtAp_CoastCtrl: type=CtAp_CoastCtrl
      CtAp_CrpCtrl: type=CtAp_CrpCtrl
      CtAp_DrvAsscCtrl: type=CtAp_DrvAsscCtrl
      CtAp_DrvTorqCoor: type=CtAp_DrvTorqCoor
      CtAp_OnePedCtrl: type=CtAp_OnePedCtrl
      CtAp_PdlAlys: type=CtAp_PdlAlys
      CtAp_VehStabyCtrl: type=CtAp_VehStabyCtrl
    connect CtAp_AccrPedlDrv.RTE_P_ChassisMgmt_AccrPedlDrvTq_Nm -> CtAp_DrvTorqCoor.RTE_R_ChassisMgmt_AccrPedlDrvTq_Nm
    connect CtAp_BrkMgmt.RTE_P_ChassisMgmt_BrkRgnActv_Flg -> CtAp_DrvTorqCoor.RTE_R_ChassisMgmt_BrkRgnActv_Flg
    connect CtAp_BrkMgmt.RTE_P_ChassisMgmt_BrkRgnTq_Nm -> CtAp_DrvTorqCoor.RTE_R_ChassisMgmt_BrkRgnTq_Nm
    connect CtAp_CoastCtrl.RTE_P_ChassisMgmt_CoastCtrlActv_Flg -> CtAp_AccrPedlDrv.RTE_R_ChassisMgmt_CoastCtrlActv_Flg
    connect CtAp_CoastCtrl.RTE_P_ChassisMgmt_CoastCtrlTq_Nm -> CtAp_AccrPedlDrv.RTE_R_ChassisMgmt_CoastCtrlTq_Nm
    connect CtAp_CrpCtrl.RTE_P_ChassisMgmt_CrpCtrlDesTq_Nm -> CtAp_DrvTorqCoor.RTE_R_ChassisMgmt_CrpCtrlDesTq_Nm
    connect CtAp_DrvAsscCtrl.RTE_P_ChassisMgmt_DrvAsscCtrlActv_Flg -> CtAp_DrvTorqCoor.RTE_R_ChassisMgmt_DrvAsscCtrlActv_Flg
    connect CtAp_DrvAsscCtrl.RTE_P_ChassisMgmt_DrvAsscCtrlTq_Nm -> CtAp_DrvTorqCoor.RTE_R_ChassisMgmt_DrvAsscCtrlTq_Nm
    connect CtAp_DrvTorqCoor.RTE_P_ChassisMgmt_DrvDmdHiPrio_Flg -> CtAp_CrpCtrl.RTE_R_ChassisMgmt_DrvDmdHiPrio_Flg
    connect CtAp_DrvTorqCoor.RTE_P_ChassisMgmt_SpdLmtSts_Flg -> CtAp_CrpCtrl.RTE_R_ChassisMgmt_SpdLmtSts_Flg
    connect CtAp_OnePedCtrl.RTE_P_ChassisMgmt_OnePedlActv_Flg -> CtAp_DrvTorqCoor.RTE_R_ChassisMgmt_OnePedlActv_Flg
    connect CtAp_OnePedCtrl.RTE_P_ChassisMgmt_OnePedlDesTq_Nm -> CtAp_DrvTorqCoor.RTE_R_ChassisMgmt_OnePedlDesTq_Nm
    connect CtAp_PdlAlys.RTE_P_ChassisMgmt_AccrPedlPosn_pct -> CtAp_AccrPedlDrv.RTE_R_ChassisMgmt_AccrPedlPosn_pct
    connect CtAp_PdlAlys.RTE_P_ChassisMgmt_BrkSts_Flg -> CtAp_BrkMgmt.RTE_R_ChassisMgmt_BrkSts_Flg
    connect CtAp_PdlAlys.RTE_P_ChassisMgmt_AccrPedlPosn_pct -> CtAp_CoastCtrl.RTE_R_ChassisMgmt_AccrPedlPosn_pct
    connect CtAp_PdlAlys.RTE_P_ChassisMgmt_BrkPedlPosn_pct -> CtAp_CrpCtrl.RTE_R_ChassisMgmt_BrkPedlPosn_pct
    connect CtAp_PdlAlys.RTE_P_ChassisMgmt_BrkStsVld_Flg -> CtAp_CrpCtrl.RTE_R_ChassisMgmt_BrkStsVld_Flg
    connect CtAp_PdlAlys.RTE_P_ChassisMgmt_AccrPedlPosn_pct -> CtAp_OnePedCtrl.RTE_R_ChassisMgmt_AccrPedlPosn_pct
    delegate CtAp_AccrPedlDrv.RTE_P_ChassisMgmt_AccrPedlDrvTq_Nm <-> outer port CtAp_ChassisMgmt/RTE_P_ChassisMgmt_AccrPedlDrvTq_Nm
    delegate CtAp_PdlAlys.RTE_P_ChassisMgmt_AccrPedlFltSts_Enum <-> outer port CtAp_ChassisMgmt/RTE_P_ChassisMgmt_AccrPedlFltSts_Enum
    delegate CtAp_PdlAlys.RTE_P_ChassisMgmt_AccrPedlPosnRaw_pct <-> outer port CtAp_ChassisMgmt/RTE_P_ChassisMgmt_AccrPedlPosnRaw_pct
    delegate CtAp_PdlAlys.RTE_P_ChassisMgmt_AccrPedlVld_Flg <-> outer port CtAp_ChassisMgmt/RTE_P_ChassisMgmt_AccrPedlVld_Flg
    delegate CtAp_CoastCtrl.RTE_P_ChassisMgmt_BrkCmpSts_Enum <-> outer port CtAp_ChassisMgmt/RTE_P_ChassisMgmt_BrkCmpSts_Enum
    delegate CtAp_DrvTorqCoor.RTE_P_ChassisMgmt_BrkCtrlSts_Flg <-> outer port CtAp_ChassisMgmt/RTE_P_ChassisMgmt_BrkCtrlSts_Flg
    delegate CtAp_PdlAlys.RTE_P_ChassisMgmt_BrkFltSts_Flg <-> outer port CtAp_ChassisMgmt/RTE_P_ChassisMgmt_BrkFltSts_Flg
    delegate CtAp_CoastCtrl.RTE_P_ChassisMgmt_CoastCtrlMCUReqSts_Enum <-> outer port CtAp_ChassisMgmt/RTE_P_ChassisMgmt_CoastCtrlMCUReqSts_Enum
    delegate CtAp_DrvTorqCoor.RTE_P_ChassisMgmt_DrvAsscCtrlOvrdSts_Flg <-> outer port CtAp_ChassisMgmt/RTE_P_ChassisMgmt_DrvAsscCtrlOvrdSts_Flg
    delegate CtAp_DrvTorqCoor.RTE_P_ChassisMgmt_DrvCoorDesTq_Nm <-> outer port CtAp_ChassisMgmt/RTE_P_ChassisMgmt_DrvCoorDesTq_Nm
    delegate CtAp_DrvTorqCoor.RTE_P_ChassisMgmt_DrvrDesTq_Nm <-> outer port CtAp_ChassisMgmt/RTE_P_ChassisMgmt_DrvrDesTq_Nm
    delegate CtAp_VehStabyCtrl.RTE_P_ChassisMgmt_IBSIntvIncTq_Nm <-> outer port CtAp_ChassisMgmt/RTE_P_ChassisMgmt_IBSIntvIncTq_Nm
    delegate CtAp_VehStabyCtrl.RTE_P_ChassisMgmt_IBSIntvIncTqActv_Flg <-> outer port CtAp_ChassisMgmt/RTE_P_ChassisMgmt_IBSIntvIncTqActv_Flg
    delegate CtAp_VehStabyCtrl.RTE_P_ChassisMgmt_IBSIntvRednTq_Nm <-> outer port CtAp_ChassisMgmt/RTE_P_ChassisMgmt_IBSIntvRednTq_Nm
    delegate CtAp_VehStabyCtrl.RTE_P_ChassisMgmt_IBSIntvRednTqActv_Flg <-> outer port CtAp_ChassisMgmt/RTE_P_ChassisMgmt_IBSIntvRednTqActv_Flg
    delegate CtAp_DrvAsscCtrl.RTE_P_ChassisMgmt_IBSVlcReqTqAvl_Flg <-> outer port CtAp_ChassisMgmt/RTE_P_ChassisMgmt_IBSVlcReqTqAvl_Flg
    delegate CtAp_OnePedCtrl.RTE_P_ChassisMgmt_OnePedlDesDecelSpd_mps2q <-> outer port CtAp_ChassisMgmt/RTE_P_ChassisMgmt_OnePedlDesDecelSpd_mps2q
    delegate CtAp_OnePedCtrl.RTE_P_ChassisMgmt_OnePedlFltSts_Flg <-> outer port CtAp_ChassisMgmt/RTE_P_ChassisMgmt_OnePedlFltSts_Flg
    delegate CtAp_PdlAlys.RTE_P_ChassisMgmt_PedlAlysDTC_16bit <-> outer port CtAp_ChassisMgmt/RTE_P_ChassisMgmt_PedlAlysDTC_16bit
    delegate CtAp_CoastCtrl.RTE_P_ChassisMgmt_VehDesDecel_mps2q <-> outer port CtAp_ChassisMgmt/RTE_P_ChassisMgmt_VehDesDecel_mps2q
    delegate CtAp_CrpCtrl.RTE_R_ComM_EPBWrkSts_Enum <-> outer port CtAp_ChassisMgmt/RTE_R_ComM_EPBWrkSts_Enum
    delegate CtAp_OnePedCtrl.RTE_R_ComM_IBSAbpActv_Flg <-> outer port CtAp_ChassisMgmt/RTE_R_ComM_IBSAbpActv_Flg
    delegate CtAp_OnePedCtrl.RTE_R_ComM_IBSAebActv_Flg <-> outer port CtAp_ChassisMgmt/RTE_R_ComM_IBSAebActv_Flg
    delegate CtAp_DrvAsscCtrl.RTE_R_ComM_IBSApaModSts_Enum <-> outer port CtAp_ChassisMgmt/RTE_R_ComM_IBSApaModSts_Enum
    delegate CtAp_DrvAsscCtrl.RTE_R_ComM_IBSApaReqTq_Nm <-> outer port CtAp_ChassisMgmt/RTE_R_ComM_IBSApaReqTq_Nm
    delegate CtAp_DrvAsscCtrl.RTE_R_ComM_IBSApaReqTqVld_Flg <-> outer port CtAp_ChassisMgmt/RTE_R_ComM_IBSApaReqTqVld_Flg
    delegate CtAp_PdlAlys.RTE_R_ComM_IBSBrkMstCylPrs_pct <-> outer port CtAp_ChassisMgmt/RTE_R_ComM_IBSBrkMstCylPrs_pct
    delegate CtAp_PdlAlys.RTE_R_ComM_IBSBrkPlgrPrs_pct <-> outer port CtAp_ChassisMgmt/RTE_R_ComM_IBSBrkPlgrPrs_pct
    delegate CtAp_PdlAlys.RTE_R_ComM_IBSBrkSts_Enum <-> outer port CtAp_ChassisMgmt/RTE_R_ComM_IBSBrkSts_Enum
    delegate CtAp_VehStabyCtrl.RTE_R_ComM_IBSDtcActv_Flg <-> outer port CtAp_ChassisMgmt/RTE_R_ComM_IBSDtcActv_Flg
    delegate CtAp_VehStabyCtrl.RTE_R_ComM_IBSDtcFlt_Flg <-> outer port CtAp_ChassisMgmt/RTE_R_ComM_IBSDtcFlt_Flg
    delegate CtAp_OnePedCtrl.RTE_R_ComM_IBSHdcSts_Enum <-> outer port CtAp_ChassisMgmt/RTE_R_ComM_IBSHdcSts_Enum
    delegate CtAp_BrkMgmt.RTE_R_ComM_IBSRbsReqTq_Nm <-> outer port CtAp_ChassisMgmt/RTE_R_ComM_IBSRbsReqTq_Nm
    delegate CtAp_BrkMgmt.RTE_R_ComM_IBSRbsReqTqVld_Flg <-> outer port CtAp_ChassisMgmt/RTE_R_ComM_IBSRbsReqTqVld_Flg
    delegate CtAp_BrkMgmt.RTE_R_ComM_IBSRbsSts_Enum <-> outer port CtAp_ChassisMgmt/RTE_R_ComM_IBSRbsSts_Enum
    delegate CtAp_VehStabyCtrl.RTE_R_ComM_IBSReqIncTq_Nm <-> outer port CtAp_ChassisMgmt/RTE_R_ComM_IBSReqIncTq_Nm
    delegate CtAp_VehStabyCtrl.RTE_R_ComM_IBSReqIncTqVld_Flg <-> outer port CtAp_ChassisMgmt/RTE_R_ComM_IBSReqIncTqVld_Flg
    delegate CtAp_VehStabyCtrl.RTE_R_ComM_IBSReqRednTq_Nm <-> outer port CtAp_ChassisMgmt/RTE_R_ComM_IBSReqRednTq_Nm
    delegate CtAp_VehStabyCtrl.RTE_R_ComM_IBSReqRednTqVld_Flg <-> outer port CtAp_ChassisMgmt/RTE_R_ComM_IBSReqRednTqVld_Flg
    delegate CtAp_OnePedCtrl.RTE_R_ComM_IBSRwuActv_Flg <-> outer port CtAp_ChassisMgmt/RTE_R_ComM_IBSRwuActv_Flg
    delegate CtAp_VehStabyCtrl.RTE_R_ComM_IBSTcsActv_Flg <-> outer port CtAp_ChassisMgmt/RTE_R_ComM_IBSTcsActv_Flg
    delegate CtAp_VehStabyCtrl.RTE_R_ComM_IBSTcsFlt_Flg <-> outer port CtAp_ChassisMgmt/RTE_R_ComM_IBSTcsFlt_Flg
    delegate CtAp_VehStabyCtrl.RTE_R_ComM_IBSVdcActv_Flg <-> outer port CtAp_ChassisMgmt/RTE_R_ComM_IBSVdcActv_Flg
    delegate CtAp_VehStabyCtrl.RTE_R_ComM_IBSVdcFlt_Flg <-> outer port CtAp_ChassisMgmt/RTE_R_ComM_IBSVdcFlt_Flg
    delegate CtAp_DrvAsscCtrl.RTE_R_ComM_IBSVlcActv_Flg <-> outer port CtAp_ChassisMgmt/RTE_R_ComM_IBSVlcActv_Flg
    delegate CtAp_DrvAsscCtrl.RTE_R_ComM_IBSVlcReqTq_Nm <-> outer port CtAp_ChassisMgmt/RTE_R_ComM_IBSVlcReqTq_Nm
    delegate CtAp_DrvAsscCtrl.RTE_R_ComM_IBSVlcReqTqVld_Flg <-> outer port CtAp_ChassisMgmt/RTE_R_ComM_IBSVlcReqTqVld_Flg
    delegate CtAp_CoastCtrl.RTE_R_ComM_IVIEnaBrkCmpMod_Enum <-> outer port CtAp_ChassisMgmt/RTE_R_ComM_IVIEnaBrkCmpMod_Enum
    delegate CtAp_OnePedCtrl.RTE_R_ComM_IVIEnaOnePedlMod_Enum <-> outer port RTE_R_Comm_IVIEnaOnePedlMod_Enum
    delegate CtAp_AccrPedlDrv.RTE_R_ErrMgmt_ChassisCtrl_8bit <-> outer port CtAp_ChassisMgmt/RTE_R_ErrMgmt_ChassisCtrl_8bit
    delegate CtAp_BrkMgmt.RTE_R_ErrMgmt_ChassisCtrl_8bit <-> outer port CtAp_ChassisMgmt/RTE_R_ErrMgmt_ChassisCtrl_8bit
    delegate CtAp_CoastCtrl.RTE_R_ErrMgmt_ChassisCtrl_8bit <-> outer port CtAp_ChassisMgmt/RTE_R_ErrMgmt_ChassisCtrl_8bit
    delegate CtAp_CrpCtrl.RTE_R_ErrMgmt_ChassisCtrl_8bit <-> outer port CtAp_ChassisMgmt/RTE_R_ErrMgmt_ChassisCtrl_8bit
    delegate CtAp_DrvAsscCtrl.RTE_R_ErrMgmt_ChassisCtrl_8bit <-> outer port CtAp_ChassisMgmt/RTE_R_ErrMgmt_ChassisCtrl_8bit
    delegate CtAp_OnePedCtrl.RTE_R_ErrMgmt_ChassisCtrl_8bit <-> outer port CtAp_ChassisMgmt/RTE_R_ErrMgmt_ChassisCtrl_8bit
    delegate CtAp_VehStabyCtrl.RTE_R_ErrMgmt_ChassisCtrl_8bit <-> outer port CtAp_ChassisMgmt/RTE_R_ErrMgmt_ChassisCtrl_8bit
    delegate CtAp_PdlAlys.RTE_R_ErrMgmt_ComFailDTC_16bit <-> outer port CtAp_ChassisMgmt/RTE_R_ErrMgmt_ComFailDTC_16bit
    delegate CtAp_AccrPedlDrv.RTE_R_GearMgmt_ActGear_Enum <-> outer port CtAp_ChassisMgmt/RTE_R_GearMgmt_ActGear_Enum
    delegate CtAp_BrkMgmt.RTE_R_GearMgmt_ActGear_Enum <-> outer port CtAp_ChassisMgmt/RTE_R_GearMgmt_ActGear_Enum
    delegate CtAp_DrvAsscCtrl.RTE_R_GearMgmt_ActGear_Enum <-> outer port CtAp_ChassisMgmt/RTE_R_GearMgmt_ActGear_Enum
    delegate CtAp_OnePedCtrl.RTE_R_GearMgmt_ActGear_Enum <-> outer port CtAp_ChassisMgmt/RTE_R_GearMgmt_ActGear_Enum
    delegate CtAp_VehStabyCtrl.RTE_R_GearMgmt_ActGear_Enum <-> outer port CtAp_ChassisMgmt/RTE_R_GearMgmt_ActGear_Enum
    delegate CtAp_CoastCtrl.RTE_R_GearMgmt_ActGear_Enum <-> outer port CtAp_ChassisMgmt/RTE_R_GearMgmt_ActGear_Enum
    delegate CtAp_CrpCtrl.RTE_R_GearMgmt_ActGear_Enum <-> outer port CtAp_ChassisMgmt/RTE_R_GearMgmt_ActGear_Enum
    delegate CtAp_OnePedCtrl.RTE_R_HvMgmt_MCUWrkModActSts_Enum <-> outer port CtAp_ChassisMgmt/RTE_R_HvMgmt_MCUWrkModActSts_Enum
    delegate CtAp_PdlAlys.RTE_R_IOAbs_AccrPedlMaiRaw_mV <-> outer port CtAp_ChassisMgmt/RTE_R_IOAbs_AccrPedlMaiRaw_mV
    delegate CtAp_PdlAlys.RTE_R_IOAbs_AccrPedlRdnRaw_mV <-> outer port CtAp_ChassisMgmt/RTE_R_IOAbs_AccrPedlRdnRaw_mV
    delegate CtAp_PdlAlys.RTE_R_IOAbs_BrkMaiRaw_Flg <-> outer port CtAp_ChassisMgmt/RTE_R_IOAbs_BrkMaiRaw_Flg
    delegate CtAp_PdlAlys.RTE_R_IOAbs_BrkRdnRaw_Flg <-> outer port CtAp_ChassisMgmt/RTE_R_IOAbs_BrkRdnRaw_Flg
    delegate CtAp_PdlAlys.RTE_R_LvMgmt_WakeUpSrc_Enum <-> outer port CtAp_ChassisMgmt/RTE_R_LvMgmt_WakeUpSrc_Enum
    delegate CtAp_AccrPedlDrv.RTE_R_ModMgmt_ActDrvMod_Enum <-> outer port CtAp_ChassisMgmt/RTE_R_ModMgmt_ActDrvMod_Enum
    delegate CtAp_CoastCtrl.RTE_R_ModMgmt_ActDrvMod_Enum <-> outer port CtAp_ChassisMgmt/RTE_R_ModMgmt_ActDrvMod_Enum
    delegate CtAp_OnePedCtrl.RTE_R_ModMgmt_ActDrvMod_Enum <-> outer port CtAp_ChassisMgmt/RTE_R_ModMgmt_ActDrvMod_Enum
    delegate CtAp_AccrPedlDrv.RTE_R_ModMgmt_HvSts_Enum <-> outer port CtAp_ChassisMgmt/RTE_R_ModMgmt_HvSts_Enum
    delegate CtAp_BrkMgmt.RTE_R_ModMgmt_HvSts_Enum <-> outer port CtAp_ChassisMgmt/RTE_R_ModMgmt_HvSts_Enum
    delegate CtAp_CoastCtrl.RTE_R_ModMgmt_HvSts_Enum <-> outer port CtAp_ChassisMgmt/RTE_R_ModMgmt_HvSts_Enum
    delegate CtAp_CrpCtrl.RTE_R_ModMgmt_HvSts_Enum <-> outer port CtAp_ChassisMgmt/RTE_R_ModMgmt_HvSts_Enum
    delegate CtAp_DrvAsscCtrl.RTE_R_ModMgmt_HvSts_Enum <-> outer port CtAp_ChassisMgmt/RTE_R_ModMgmt_HvSts_Enum
    delegate CtAp_OnePedCtrl.RTE_R_ModMgmt_HvSts_Enum <-> outer port CtAp_ChassisMgmt/RTE_R_ModMgmt_HvSts_Enum
    delegate CtAp_VehStabyCtrl.RTE_R_ModMgmt_HvSts_Enum <-> outer port CtAp_ChassisMgmt/RTE_R_ModMgmt_HvSts_Enum
    delegate CtAp_VehStabyCtrl.RTE_R_TorqPahMgmt_EmacQstyMaxTq_Nm <-> outer port CtAp_ChassisMgmt/RTE_R_TorqPahMgmt_EmacQstyMaxTq_Nm
    delegate CtAp_VehStabyCtrl.RTE_R_TorqPahMgmt_EmacQstyMinTq_Nm <-> outer port CtAp_ChassisMgmt/RTE_R_TorqPahMgmt_EmacQstyMinTq_Nm
    delegate CtAp_VehStabyCtrl.RTE_R_TorqPahMgmt_IBSIntvTqSts_Enum <-> outer port CtAp_ChassisMgmt/RTE_R_TorqPahMgmt_IBSIntvTqSts_Enum
    delegate CtAp_DrvTorqCoor.RTE_R_TorqPahMgmt_VehSpdLmtSts_Flg <-> outer port CtAp_ChassisMgmt/RTE_R_TorqPahMgmt_VehSpdLmtSts_Flg
    delegate CtAp_DrvTorqCoor.RTE_R_TorqPahMgmt_VehSpdLmtTq_Nm <-> outer port CtAp_ChassisMgmt/RTE_R_TorqPahMgmt_VehSpdLmtTq_Nm
    delegate CtAp_CoastCtrl.RTE_R_VehMot_Acclr2Tq_Nm <-> outer port CtAp_ChassisMgmt/RTE_R_VehMot_Acclr2Tq_Nm
    delegate CtAp_OnePedCtrl.RTE_R_VehMot_Acclr2Tq_Nm <-> outer port CtAp_ChassisMgmt/RTE_R_VehMot_Acclr2Tq_Nm
    delegate CtAp_CoastCtrl.RTE_R_VehMot_AcclrPrpCurr_mps2q <-> outer port CtAp_ChassisMgmt/RTE_R_VehMot_AcclrPrpCurr_mps2q
    delegate CtAp_OnePedCtrl.RTE_R_VehMot_AcclrPrpCurr_mps2q <-> outer port CtAp_ChassisMgmt/RTE_R_VehMot_AcclrPrpCurr_mps2q
    delegate CtAp_CrpCtrl.RTE_R_VehMot_SlopGrd_deg <-> outer port CtAp_ChassisMgmt/RTE_R_VehMot_SlopGrd_deg
    delegate CtAp_AccrPedlDrv.RTE_R_VehMot_VehDirDif_Flg <-> outer port CtAp_ChassisMgmt/RTE_R_VehMot_VehDirDif_Flg
    delegate CtAp_CrpCtrl.RTE_R_VehMot_VehDirDif_Flg <-> outer port CtAp_ChassisMgmt/RTE_R_VehMot_VehDirDif_Flg
    delegate CtAp_OnePedCtrl.RTE_R_VehMot_VehDirDif_Flg <-> outer port CtAp_ChassisMgmt/RTE_R_VehMot_VehDirDif_Flg
    delegate CtAp_OnePedCtrl.RTE_R_VehMot_VehDragTq_Nm <-> outer port CtAp_ChassisMgmt/RTE_R_VehMot_VehDragTq_Nm
    delegate CtAp_AccrPedlDrv.RTE_R_VehMot_VehSpd_kph <-> outer port CtAp_ChassisMgmt/RTE_R_VehMot_VehSpd_kph
    delegate CtAp_BrkMgmt.RTE_R_VehMot_VehSpd_kph <-> outer port CtAp_ChassisMgmt/RTE_R_VehMot_VehSpd_kph
    delegate CtAp_CoastCtrl.RTE_R_VehMot_VehSpd_kph <-> outer port CtAp_ChassisMgmt/RTE_R_VehMot_VehSpd_kph
    delegate CtAp_CrpCtrl.RTE_R_VehMot_VehSpd_kph <-> outer port CtAp_ChassisMgmt/RTE_R_VehMot_VehSpd_kph
    delegate CtAp_OnePedCtrl.RTE_R_VehMot_VehSpd_kph <-> outer port CtAp_ChassisMgmt/RTE_R_VehMot_VehSpd_kph
    delegate CtAp_AccrPedlDrv.RTE_R_VehMot_VehSpdVld_Flg <-> outer port CtAp_ChassisMgmt/RTE_R_VehMot_VehSpdVld_Flg
    delegate CtAp_CoastCtrl.RTE_R_VehMot_VehSpdVld_Flg <-> outer port CtAp_ChassisMgmt/RTE_R_VehMot_VehSpdVld_Flg
    delegate CtAp_CrpCtrl.RTE_R_VehMot_VehSpdVld_Flg <-> outer port CtAp_ChassisMgmt/RTE_R_VehMot_VehSpdVld_Flg
    delegate CtAp_OnePedCtrl.RTE_R_VehMot_VehSpdVld_Flg <-> outer port CtAp_ChassisMgmt/RTE_R_VehMot_VehSpdVld_Flg
  9 x swc implementation:
    CtAp_AccrPedlDrv_Implementation: behavior=CtAp_AccrPedlDrv_InternalBehavior
      code-descriptors:
        code Default: artifact-descriptors=autosar-engineering-object={short-label=Default, category=SWOBJ}
    CtAp_BrkMgmt_Implementation: behavior=CtAp_BrkMgmt_InternalBehavior
      code-descriptors:
        code Default: artifact-descriptors=autosar-engineering-object={short-label=Default, category=SWOBJ}
    CtAp_CoastCtrl_Implementation: behavior=CtAp_CoastCtrl_InternalBehavior
      code-descriptors:
        code Default: artifact-descriptors=autosar-engineering-object={short-label=Default, category=SWOBJ}
    CtAp_CrpCtrl_Implementation: behavior=CtAp_CrpCtrl_InternalBehavior
      code-descriptors:
        code Default: artifact-descriptors=autosar-engineering-object={short-label=Default, category=SWOBJ}
    CtAp_DrvAsscCtrl_Implementation: behavior=CtAp_DrvAsscCtrl_InternalBehavior
      code-descriptors:
        code Default: artifact-descriptors=autosar-engineering-object={short-label=Default, category=SWOBJ}
    CtAp_DrvTorqCoor_Implementation: behavior=CtAp_DrvTorqCoor_InternalBehavior
      code-descriptors:
        code Default: artifact-descriptors=autosar-engineering-object={short-label=Default, category=SWOBJ}
    CtAp_OnePedCtrl_Implementation: behavior=CtAp_OnePedCtrl_InternalBehavior
      code-descriptors:
        code Default: artifact-descriptors=autosar-engineering-object={short-label=Default, category=SWOBJ}
    CtAp_PdlAlys_Implementation: behavior=CtAp_PdlAlys_InternalBehavior
      code-descriptors:
        code Default: artifact-descriptors=autosar-engineering-object={short-label=Default, category=SWOBJ}
    CtAp_VehStabyCtrl_Implementation: behavior=CtAp_VehStabyCtrl_InternalBehavior
      code-descriptors:
        code Default: artifact-descriptors=autosar-engineering-object={short-label=Default, category=SWOBJ}
package /PortInterfaces
  87 x sender receiver interface:
    IF_ChassisMgmt_AccrPedlDrvTq_Nm: invalidation-policy{data-element=tec_ChassisMgmt_AccrPedlDrvTq_Nm, handle-invalid=DONT-INVALIDATE}
      data tec_ChassisMgmt_AccrPedlDrvTq_Nm: type=float32
    IF_ChassisMgmt_AccrPedlFltSts_Enum: invalidation-policy{data-element=tec_ChassisMgmt_AccrPedlFltSts_Enum, handle-invalid=DONT-INVALIDATE}
      data tec_ChassisMgmt_AccrPedlFltSts_Enum: type=uint8
    IF_ChassisMgmt_AccrPedlPosn_pct: invalidation-policy{data-element=tec_ChassisMgmt_AccrPedlPosn_pct, handle-invalid=DONT-INVALIDATE}
      data tec_ChassisMgmt_AccrPedlPosn_pct: type=float32
    IF_ChassisMgmt_AccrPedlPosnRaw_pct: invalidation-policy{data-element=tec_ChassisMgmt_AccrPedlPosnRaw_pct, handle-invalid=DONT-INVALIDATE}
      data tec_ChassisMgmt_AccrPedlPosnRaw_pct: type=float32
    IF_ChassisMgmt_AccrPedlVld_Flg: invalidation-policy{data-element=tec_ChassisMgmt_AccrPedlVld_Flg, handle-invalid=DONT-INVALIDATE}
      data tec_ChassisMgmt_AccrPedlVld_Flg: type=boolean
    IF_ChassisMgmt_BrkCmpSts_Enum: invalidation-policy{data-element=tec_ChassisMgmt_BrkCmpSts_Enum, handle-invalid=DONT-INVALIDATE}
      data tec_ChassisMgmt_BrkCmpSts_Enum: type=uint8
    IF_ChassisMgmt_BrkCtrlSts_Flg: invalidation-policy{data-element=tec_ChassisMgmt_BrkCtrlSts_Flg, handle-invalid=DONT-INVALIDATE}
      data tec_ChassisMgmt_BrkCtrlSts_Flg: type=boolean
    IF_ChassisMgmt_BrkFltSts_Flg: invalidation-policy{data-element=tec_ChassisMgmt_BrkFltSts_Flg, handle-invalid=DONT-INVALIDATE}
      data tec_ChassisMgmt_BrkFltSts_Flg: type=boolean
    IF_ChassisMgmt_BrkPedlPosn_pct: invalidation-policy{data-element=tec_ChassisMgmt_BrkPedlPosn_pct, handle-invalid=DONT-INVALIDATE}
      data tec_ChassisMgmt_BrkPedlPosn_pct: type=float32
    IF_ChassisMgmt_BrkRgnActv_Flg: invalidation-policy{data-element=tec_ChassisMgmt_BrkRgnActv_Flg, handle-invalid=DONT-INVALIDATE}
      data tec_ChassisMgmt_BrkRgnActv_Flg: type=boolean
    IF_ChassisMgmt_BrkRgnTq_Nm: invalidation-policy{data-element=tec_ChassisMgmt_BrkRgnTq_Nm, handle-invalid=DONT-INVALIDATE}
      data tec_ChassisMgmt_BrkRgnTq_Nm: type=float32
    IF_ChassisMgmt_BrkSts_Flg: invalidation-policy{data-element=tec_ChassisMgmt_BrkSts_Flg, handle-invalid=DONT-INVALIDATE}
      data tec_ChassisMgmt_BrkSts_Flg: type=boolean
    IF_ChassisMgmt_BrkStsVld_Flg: invalidation-policy{data-element=tec_ChassisMgmt_BrkStsVld_Flg, handle-invalid=DONT-INVALIDATE}
      data tec_ChassisMgmt_BrkStsVld_Flg: type=boolean
    IF_ChassisMgmt_CoastCtrlActv_Flg: invalidation-policy{data-element=tec_ChassisMgmt_CoastCtrlActv_Flg, handle-invalid=DONT-INVALIDATE}
      data tec_ChassisMgmt_CoastCtrlActv_Flg: type=boolean
    IF_ChassisMgmt_CoastCtrlMCUReqSts_Enum: invalidation-policy{data-element=tec_ChassisMgmt_CoastCtrlMCUReqSts_Enum, handle-invalid=DONT-INVALIDATE}
      data tec_ChassisMgmt_CoastCtrlMCUReqSts_Enum: type=uint8
    IF_ChassisMgmt_CoastCtrlTq_Nm: invalidation-policy{data-element=tec_ChassisMgmt_CoastCtrlTq_Nm, handle-invalid=DONT-INVALIDATE}
      data tec_ChassisMgmt_CoastCtrlTq_Nm: type=float32
    IF_ChassisMgmt_CrpCtrlDesTq_Nm: invalidation-policy{data-element=tec_ChassisMgmt_CrpCtrlDesTq_Nm, handle-invalid=DONT-INVALIDATE}
      data tec_ChassisMgmt_CrpCtrlDesTq_Nm: type=float32
    IF_ChassisMgmt_DrvAsscCtrlActv_Flg: invalidation-policy{data-element=tec_ChassisMgmt_DrvAsscCtrlActv_Flg, handle-invalid=DONT-INVALIDATE}
      data tec_ChassisMgmt_DrvAsscCtrlActv_Flg: type=boolean
    IF_ChassisMgmt_DrvAsscCtrlOvrdSts_Flg: invalidation-policy{data-element=tec_ChassisMgmt_DrvAsscCtrlOvrdSts_Flg, handle-invalid=DONT-INVALIDATE}
      data tec_ChassisMgmt_DrvAsscCtrlOvrdSts_Flg: type=boolean
    IF_ChassisMgmt_DrvAsscCtrlTq_Nm: invalidation-policy{data-element=tec_ChassisMgmt_DrvAsscCtrlTq_Nm, handle-invalid=DONT-INVALIDATE}
      data tec_ChassisMgmt_DrvAsscCtrlTq_Nm: type=float32
    IF_ChassisMgmt_DrvCoorDesTq_Nm: invalidation-policy{data-element=tec_ChassisMgmt_DrvCoorDesTq_Nm, handle-invalid=DONT-INVALIDATE}
      data tec_ChassisMgmt_DrvCoorDesTq_Nm: type=float32
    IF_ChassisMgmt_DrvDmdHiPrio_Flg: invalidation-policy{data-element=tec_ChassisMgmt_DrvDmdHiPrio_Flg, handle-invalid=DONT-INVALIDATE}
      data tec_ChassisMgmt_DrvDmdHiPrio_Flg: type=boolean
    IF_ChassisMgmt_DrvrDesTq_Nm: invalidation-policy{data-element=tec_ChassisMgmt_DrvrDesTq_Nm, handle-invalid=DONT-INVALIDATE}
      data tec_ChassisMgmt_DrvrDesTq_Nm: type=float32
    IF_ChassisMgmt_IBSIntvIncTq_Nm: invalidation-policy{data-element=tec_ChassisMgmt_IBSIntvIncTq_Nm, handle-invalid=DONT-INVALIDATE}
      data tec_ChassisMgmt_IBSIntvIncTq_Nm: type=float32
    IF_ChassisMgmt_IBSIntvIncTqActv_Flg: invalidation-policy{data-element=tec_ChassisMgmt_IBSIntvIncTqActv_Flg, handle-invalid=DONT-INVALIDATE}
      data tec_ChassisMgmt_IBSIntvIncTqActv_Flg: type=boolean
    IF_ChassisMgmt_IBSIntvRednTq_Nm: invalidation-policy{data-element=tec_ChassisMgmt_IBSIntvRednTq_Nm, handle-invalid=DONT-INVALIDATE}
      data tec_ChassisMgmt_IBSIntvRednTq_Nm: type=float32
    IF_ChassisMgmt_IBSIntvRednTqActv_Flg: invalidation-policy{data-element=tec_ChassisMgmt_IBSIntvRednTqActv_Flg, handle-invalid=DONT-INVALIDATE}
      data tec_ChassisMgmt_IBSIntvRednTqActv_Flg: type=boolean
    IF_ChassisMgmt_IBSVlcReqTqAvl_Flg: invalidation-policy{data-element=tec_ChassisMgmt_IBSVlcReqTqAvl_Flg, handle-invalid=DONT-INVALIDATE}
      data tec_ChassisMgmt_IBSVlcReqTqAvl_Flg: type=boolean
    IF_ChassisMgmt_OnePedlActv_Flg: invalidation-policy{data-element=tec_ChassisMgmt_OnePedlActv_Flg, handle-invalid=DONT-INVALIDATE}
      data tec_ChassisMgmt_OnePedlActv_Flg: type=boolean
    IF_ChassisMgmt_OnePedlDesDecelSpd_mps2q: invalidation-policy{data-element=tec_ChassisMgmt_OnePedlDesDecelSpd_mps2q, handle-invalid=DONT-INVALIDATE}
      data tec_ChassisMgmt_OnePedlDesDecelSpd_mps2q: type=float32
    IF_ChassisMgmt_OnePedlDesTq_Nm: invalidation-policy{data-element=tec_ChassisMgmt_OnePedlDesTq_Nm, handle-invalid=DONT-INVALIDATE}
      data tec_ChassisMgmt_OnePedlDesTq_Nm: type=float32
    IF_ChassisMgmt_OnePedlFltSts_Flg: invalidation-policy{data-element=tec_ChassisMgmt_OnePedlFltSts_Flg, handle-invalid=DONT-INVALIDATE}
      data tec_ChassisMgmt_OnePedlFltSts_Flg: type=boolean
    IF_ChassisMgmt_PedlAlysDTC_16bit: invalidation-policy{data-element=tec_ChassisMgmt_PedlAlysDTC_16bit, handle-invalid=DONT-INVALIDATE}
      data tec_ChassisMgmt_PedlAlysDTC_16bit: type=uint16
    IF_ChassisMgmt_SpdLmtSts_Flg: invalidation-policy{data-element=tec_ChassisMgmt_SpdLmtSts_Flg, handle-invalid=DONT-INVALIDATE}
      data tec_ChassisMgmt_SpdLmtSts_Flg: type=boolean
    IF_ChassisMgmt_VehDesDecel_mps2q: invalidation-policy{data-element=tec_ChassisMgmt_BrkCmpDesDecel_mps2q, handle-invalid=DONT-INVALIDATE}
      data tec_ChassisMgmt_BrkCmpDesDecel_mps2q: type=float32
    IF_ComM_EPBWrkSts_Enum: invalidation-policy{data-element=tec_ComM_EPBWrkSts_Enum, handle-invalid=DONT-INVALIDATE}
      data tec_ComM_EPBWrkSts_Enum: type=uint8
    IF_ComM_IBSAbpActv_Flg: invalidation-policy{data-element=tec_ComM_IBSAbpActv_Flg, handle-invalid=DONT-INVALIDATE}
      data tec_ComM_IBSAbpActv_Flg: type=boolean
    IF_ComM_IBSAebActv_Flg: invalidation-policy{data-element=tec_ComM_IBSAebActv_Flg, handle-invalid=DONT-INVALIDATE}
      data tec_ComM_IBSAebActv_Flg: type=boolean
    IF_ComM_IBSApaModSts_Enum: invalidation-policy{data-element=tec_ComM_IBSApaModSts_Enum, handle-invalid=DONT-INVALIDATE}
      data tec_ComM_IBSApaModSts_Enum: type=uint8
    IF_ComM_IBSApaReqTq_Nm: invalidation-policy{data-element=tec_ComM_IBSApaReqTq_Nm, handle-invalid=DONT-INVALIDATE}
      data tec_ComM_IBSApaReqTq_Nm: type=float32
    IF_ComM_IBSApaReqTqVld_Flg: invalidation-policy{data-element=tec_ComM_IBSApaReqTqVld_Flg, handle-invalid=DONT-INVALIDATE}
      data tec_ComM_IBSApaReqTqVld_Flg: type=boolean
    IF_ComM_IBSBrkMstCylPrs_pct: invalidation-policy{data-element=tec_ComM_IBSBrkMstCylPrs_pct, handle-invalid=DONT-INVALIDATE}
      data tec_ComM_IBSBrkMstCylPrs_pct: type=float32
    IF_ComM_IBSBrkPlgrPrs_pct: invalidation-policy{data-element=tec_ComM_IBSBrkPlgrPrs_pct, handle-invalid=DONT-INVALIDATE}
      data tec_ComM_IBSBrkPlgrPrs_pct: type=float32
    IF_ComM_IBSBrkSts_Enum: invalidation-policy{data-element=tec_ComM_IBSBrkSts_Enum, handle-invalid=DONT-INVALIDATE}
      data tec_ComM_IBSBrkSts_Enum: type=uint8
    IF_ComM_IBSDtcActv_Flg: invalidation-policy{data-element=tec_ComM_IBSDtcActv_Flg, handle-invalid=DONT-INVALIDATE}
      data tec_ComM_IBSDtcActv_Flg: type=boolean
    IF_ComM_IBSDtcFlt_Flg: invalidation-policy{data-element=tec_ComM_IBSDtcFlt_Flg, handle-invalid=DONT-INVALIDATE}
      data tec_ComM_IBSDtcFlt_Flg: type=boolean
    IF_ComM_IBSHdcSts_Enum: invalidation-policy{data-element=tec_ComM_IBSHdcSts_Enum, handle-invalid=DONT-INVALIDATE}
      data tec_ComM_IBSHdcSts_Enum: type=uint8
    IF_ComM_IBSRbsReqTq_Nm: invalidation-policy{data-element=tec_ComM_IBSRbsReqTq_Nm, handle-invalid=DONT-INVALIDATE}
      data tec_ComM_IBSRbsReqTq_Nm: type=float32
    IF_ComM_IBSRbsReqTqVld_Flg: invalidation-policy{data-element=tec_ComM_IBSRbsReqTqVld_Flg, handle-invalid=DONT-INVALIDATE}
      data tec_ComM_IBSRbsReqTqVld_Flg: type=boolean
    IF_ComM_IBSRbsSts_Enum: invalidation-policy{data-element=tec_ComM_IBSRbsSts_Enum, handle-invalid=DONT-INVALIDATE}
      data tec_ComM_IBSRbsSts_Enum: type=uint8
    IF_ComM_IBSReqIncTq_Nm: invalidation-policy{data-element=tec_ComM_IBSReqIncTq_Nm, handle-invalid=DONT-INVALIDATE}
      data tec_ComM_IBSReqIncTq_Nm: type=float32
    IF_ComM_IBSReqIncTqVld_Flg: invalidation-policy{data-element=tec_ComM_IBSReqIncTqVld_Flg, handle-invalid=DONT-INVALIDATE}
      data tec_ComM_IBSReqIncTqVld_Flg: type=boolean
    IF_ComM_IBSReqRednTq_Nm: invalidation-policy{data-element=tec_ComM_IBSReqRednTq_Nm, handle-invalid=DONT-INVALIDATE}
      data tec_ComM_IBSReqRednTq_Nm: type=float32
    IF_ComM_IBSReqRednTqVld_Flg: invalidation-policy{data-element=tec_ComM_IBSReqRednTqVld_Flg, handle-invalid=DONT-INVALIDATE}
      data tec_ComM_IBSReqRednTqVld_Flg: type=boolean
    IF_ComM_IBSRwuActv_Flg: invalidation-policy{data-element=tec_ComM_IBSRwuActv_Flg, handle-invalid=DONT-INVALIDATE}
      data tec_ComM_IBSRwuActv_Flg: type=boolean
    IF_ComM_IBSTcsActv_Flg: invalidation-policy{data-element=tec_ComM_IBSTcsActv_Flg, handle-invalid=DONT-INVALIDATE}
      data tec_ComM_IBSTcsActv_Flg: type=boolean
    IF_ComM_IBSTcsFlt_Flg: invalidation-policy{data-element=tec_ComM_IBSTcsFlt_Flg, handle-invalid=DONT-INVALIDATE}
      data tec_ComM_IBSTcsFlt_Flg: type=boolean
    IF_ComM_IBSVdcActv_Flg: invalidation-policy{data-element=tec_ComM_IBSVdcActv_Flg, handle-invalid=DONT-INVALIDATE}
      data tec_ComM_IBSVdcActv_Flg: type=boolean
    IF_ComM_IBSVdcFlt_Flg: invalidation-policy{data-element=tec_ComM_IBSVdcFlt_Flg, handle-invalid=DONT-INVALIDATE}
      data tec_ComM_IBSVdcFlt_Flg: type=boolean
    IF_ComM_IBSVlcActv_Flg: invalidation-policy{data-element=tec_ComM_IBSVlcActv_Flg, handle-invalid=DONT-INVALIDATE}
      data tec_ComM_IBSVlcActv_Flg: type=boolean
    IF_ComM_IBSVlcReqTq_Nm: invalidation-policy{data-element=tec_ComM_IBSVlcReqTq_Nm, handle-invalid=DONT-INVALIDATE}
      data tec_ComM_IBSVlcReqTq_Nm: type=float32
    IF_ComM_IBSVlcReqTqVld_Flg: invalidation-policy{data-element=tec_ComM_IBSVlcReqTqVld_Flg, handle-invalid=DONT-INVALIDATE}
      data tec_ComM_IBSVlcReqTqVld_Flg: type=boolean
    IF_ComM_IVIEnaBrkCmpMod_Enum: invalidation-policy{data-element=tec_ComM_IVIEnaBrkCmpMod_Enum, handle-invalid=DONT-INVALIDATE}
      data tec_ComM_IVIEnaBrkCmpMod_Enum: type=uint8
    IF_ComM_IVIEnaOnePedlMod_Enum: invalidation-policy{data-element=tec_ComM_IVIEnaOnePedlMod_Enum, handle-invalid=DONT-INVALIDATE}
      data tec_ComM_IVIEnaOnePedlMod_Enum: type=uint8
    IF_ErrMgmt_ChassisCtrl_8bit: invalidation-policy{data-element=tec_ErrMgmt_ChassisCtrl_8bit, handle-invalid=DONT-INVALIDATE}
      data tec_ErrMgmt_ChassisCtrl_8bit: type=uint8
    IF_ErrMgmt_ComFailDTC_16bit: invalidation-policy{data-element=tec_ErrMgmt_ComFailDTC_16bit, handle-invalid=DONT-INVALIDATE}
      data tec_ErrMgmt_ComFailDTC_16bit: type=uint16
    IF_GearMgmt_ActGear_Enum: invalidation-policy{data-element=tec_GearMgmt_ActGear_Enum, handle-invalid=DONT-INVALIDATE}
      data tec_GearMgmt_ActGear_Enum: type=uint8
    IF_HvMgmt_MCUWrkModActSts_Enum: invalidation-policy{data-element=tec_HvMgmt_MCUWrkModActSts_Enum, handle-invalid=DONT-INVALIDATE}
      data tec_HvMgmt_MCUWrkModActSts_Enum: type=uint8
    IF_IOAbs_AccrPedlMaiRaw_mV: invalidation-policy{data-element=tec_IOAbs_AccrPedlMaiRaw_mV, handle-invalid=DONT-INVALIDATE}
      data tec_IOAbs_AccrPedlMaiRaw_mV: type=uint16
    IF_IOAbs_AccrPedlRdnRaw_mV: invalidation-policy{data-element=tec_IOAbs_AccrPedlRdnRaw_mV, handle-invalid=DONT-INVALIDATE}
      data tec_IOAbs_AccrPedlRdnRaw_mV: type=uint16
    IF_IOAbs_BrkMaiRaw_Flg: invalidation-policy{data-element=tec_IOAbs_BrkMaiRaw_Flg, handle-invalid=DONT-INVALIDATE}
      data tec_IOAbs_BrkMaiRaw_Flg: type=boolean
    IF_IOAbs_BrkRdnRaw_Flg: invalidation-policy{data-element=tec_IOAbs_BrkRdnRaw_Flg, handle-invalid=DONT-INVALIDATE}
      data tec_IOAbs_BrkRdnRaw_Flg: type=boolean
    IF_LvMgmt_WakeUpSrc_Enum: invalidation-policy{data-element=tec_LvMgmt_WakeUpSrc_Enum, handle-invalid=DONT-INVALIDATE}
      data tec_LvMgmt_WakeUpSrc_Enum: type=uint8
    IF_ModMgmt_ActDrvMod_Enum: invalidation-policy{data-element=tec_ModMgmt_ActDrvMod_Enum, handle-invalid=DONT-INVALIDATE}
      data tec_ModMgmt_ActDrvMod_Enum: type=uint8
    IF_ModMgmt_HvSts_Enum: invalidation-policy{data-element=tec_ModMgmt_HvSts_Enum, handle-invalid=DONT-INVALIDATE}
      data tec_ModMgmt_HvSts_Enum: type=uint8
    IF_TorqPahMgmt_EmacQstyMaxTq_Nm: invalidation-policy{data-element=tec_TorqPahMgmt_EmacQstyMaxTq_Nm, handle-invalid=DONT-INVALIDATE}
      data tec_TorqPahMgmt_EmacQstyMaxTq_Nm: type=float32
    IF_TorqPahMgmt_EmacQstyMinTq_Nm: invalidation-policy{data-element=tec_TorqPahMgmt_EmacQstyMinTq_Nm, handle-invalid=DONT-INVALIDATE}
      data tec_TorqPahMgmt_EmacQstyMinTq_Nm: type=float32
    IF_TorqPahMgmt_IBSIntvTqSts_Enum: invalidation-policy{data-element=tec_TorqPahMgmt_IBSIntvTqSts_Enum, handle-invalid=DONT-INVALIDATE}
      data tec_TorqPahMgmt_IBSIntvTqSts_Enum: type=uint8
    IF_TorqPahMgmt_VehSpdLmtSts_Flg: invalidation-policy{data-element=tec_TorqPahMgmt_VehSpdLmtSts_Flg, handle-invalid=DONT-INVALIDATE}
      data tec_TorqPahMgmt_VehSpdLmtSts_Flg: type=boolean
    IF_TorqPahMgmt_VehSpdLmtTq_Nm: invalidation-policy{data-element=tec_TorqPahMgmt_VehSpdLmtTq_Nm, handle-invalid=DONT-INVALIDATE}
      data tec_TorqPahMgmt_VehSpdLmtTq_Nm: type=float32
    IF_VehMot_Acclr2Tq_Nm: invalidation-policy{data-element=tec_VehMot_Acclr2Tq_Nm, handle-invalid=DONT-INVALIDATE}
      data tec_VehMot_Acclr2Tq_Nm: type=float32
    IF_VehMot_AcclrPrpCurr_mps2q: invalidation-policy{data-element=tec_VehMot_AcclrPrpCurr_mps2q, handle-invalid=DONT-INVALIDATE}
      data tec_VehMot_AcclrPrpCurr_mps2q: type=float32
    IF_VehMot_SlopGrd_deg: invalidation-policy{data-element=tec_VehMot_SlopGrd_deg, handle-invalid=DONT-INVALIDATE}
      data tec_VehMot_SlopGrd_deg: type=sint8
    IF_VehMot_VehDirDif_Flg: invalidation-policy{data-element=tec_VehMot_VehDirDif_Flg, handle-invalid=DONT-INVALIDATE}
      data tec_VehMot_VehDirDif_Flg: type=boolean
    IF_VehMot_VehDragTq_Nm: invalidation-policy{data-element=tec_VehMot_VehDragTq_Nm, handle-invalid=DONT-INVALIDATE}
      data tec_VehMot_VehDragTq_Nm: type=float32
    IF_VehMot_VehSpd_kph: invalidation-policy{data-element=tec_VehMot_VehSpd_kph, handle-invalid=DONT-INVALIDATE}
      data tec_VehMot_VehSpd_kph: type=float32
    IF_VehMot_VehSpdVld_Flg: invalidation-policy{data-element=tec_VehMot_VehSpdVld_Flg, handle-invalid=DONT-INVALIDATE}
      data tec_VehMot_VehSpdVld_Flg: type=boolean
